VERSION ""

NS_ :

BS_:

BU_: CAN_open_MASTER MAXON RES AREO_PRESSURE_SENS DV_BOARD RPI_LOGGER AREO_TEMP_SENS ANGLE_SENSOR BUZZER BRAKE_LIGHT MAIN SW LV_BMS Power_Module HV_BMS Pedals_frame GPS2CAN ADU FS_Datalogger
VAL_TABLE_ Service_brake_state_enum 3 "Service_brake_state_available" 2 "Service_brake_state_engaged" 1 "Service_brake_state_disengaged" ;
VAL_TABLE_ AMI_state_enum 6 "AMI_state_autocross" 5 "AMI_state_inspection" 4 "AMI_state_braketest" 3 "AMI_state_trackdrive" 2 "AMI_state_skidpad" 1 "AMI_state_acceleration" ;
VAL_TABLE_ EBS_state_enum 3 "EBS_state_activated" 2 "EBS_state_armed" 1 "EBS_state_unavailable" ;
VAL_TABLE_ AS_state_enum 5 "AS_state_finish" 4 "AS_state_emergency_brake" 3 "AS_state_driving " 2 "AS_state_ready" 1 "AS_state_off" ;

BO_ 6 ACCU_FAN_SPEED_REQUEST: 2 SW
 SG_ AccuFunSpeedSet : 8|8@1+ (1,0) [0|100] "%"  BRAKE_LIGHT
 SG_ AccuFunSpeedIncrease : 0|8@1- (1,0) [-100|100] "%"  BRAKE_LIGHT

BO_ 28 ACCU_FAN_SPEED: 1 BRAKE_LIGHT
 SG_ AccuFunSpeed : 0|8@1+ (1,0) [0|100] "%"  ADU

BO_ 31 MAIN_Driver_Flags: 8 MAIN
 SG_ amkModuleFlags : 8|8@1+ (1,0) [0|255] ""  SW,ADU
 SG_ currentDriver : 0|8@1+ (1,0) [0|255] ""  SW,ADU

BO_ 39 MAIN_PBalance_Osteer: 8 MAIN
 SG_ oversteer : 32|32@1+ (1,0) [0|4294967295] ""  SW,ADU
 SG_ powerBalance : 0|32@1+ (1,0) [0|4294967295] ""  SW,ADU

BO_ 38 MAIN_O_P_Q: 8 MAIN
 SG_ Q : 48|16@1+ (1,0) [0|65535] ""  SW,ADU
 SG_ P : 32|16@1+ (1,0) [0|65535] ""  SW,ADU
 SG_ O : 0|32@1+ (1,0) [0|4294967295] ""  SW,ADU

BO_ 37 MAIN_KL: 8 MAIN
 SG_ L : 32|32@1+ (1,0) [0|4294967295] ""  SW,ADU
 SG_ K : 0|32@1+ (1,0) [0|4294967295] ""  SW,ADU

BO_ 36 MAIN_YawSet_TVSpeed: 8 MAIN
 SG_ TVStartSpeed : 32|32@1+ (1,0) [0|4294967295] ""  SW,ADU
 SG_ yawSetpoint : 0|32@1+ (1,0) [0|4294967295] ""  SW,ADU

BO_ 35 MAIN_CFilter_PLimit: 8 MAIN
 SG_ powerLimit : 32|32@1+ (1,0) [0|4294967295] ""  SW,ADU
 SG_ complFilter : 0|32@1+ (1,0) [0|4294967295] ""  SW,ADU

BO_ 34 MAIN_Kd: 8 MAIN
 SG_ TCkd : 32|32@1+ (1,0) [0|4294967295] ""  SW,ADU
 SG_ TVKd : 0|32@1+ (1,0) [0|4294967295] ""  SW,ADU

BO_ 33 MAIN_Ki: 8 MAIN
 SG_ TCKi : 32|32@1+ (1,0) [0|4294967295] ""  SW,ADU
 SG_ TVKi : 0|32@1+ (1,0) [0|4294967295] ""  SW,ADU

BO_ 32 MAIN_Kp: 8 MAIN
 SG_ TCKp : 32|32@1+ (1,0) [0|4294967295] ""  SW,ADU
 SG_ TVKp : 0|32@1+ (1,0) [0|4294967295] ""  SW,ADU

BO_ 1034 LV_BMS_REQUEST_Frame: 1 SW
 SG_ LV_BMS_REQUEST_PowerCycle : 0|8@1+ (1,0) [0|255] ""  SW

BO_ 1328 JAGGORACY_PROC: 8 HV_BMS
 SG_ JAGGORACY_PROC : 0|8@1- (1,0) [-128|127] ""  ADU

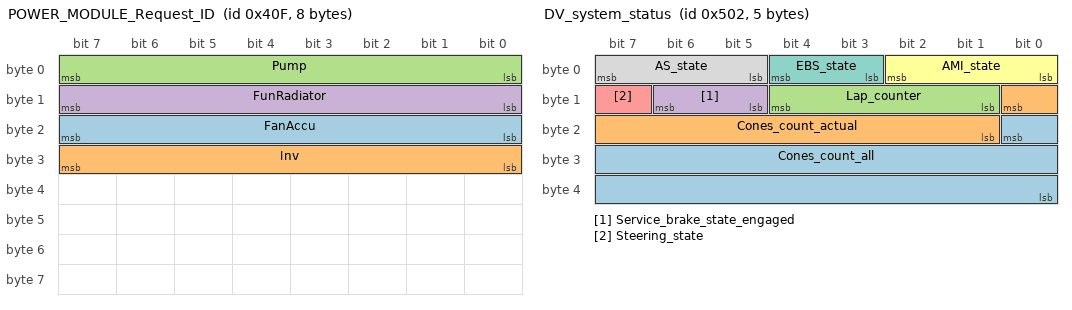
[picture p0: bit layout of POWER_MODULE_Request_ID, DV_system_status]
BO_ 1039 POWER_MODULE_Request_ID: 8 SW
 SG_ FanAccu : 23|8@0+ (1,0) [0|255] ""  Power_Module
 SG_ Inv : 31|8@0+ (1,0) [0|255] ""  Power_Module
 SG_ Pump : 7|8@0+ (1,0) [0|255] ""  Power_Module
 SG_ FunRadiator : 15|8@0+ (1,0) [0|255] ""  Power_Module

BO_ 1031 GPS_FRAME_7: 8 GPS2CAN

BO_ 1030 GPS_FRAME_6: 8 GPS2CAN

BO_ 1029 GPS_FRAME_5: 8 GPS2CAN

BO_ 1794 MAXON_NMT_Monitoring: 8 MAXON

BO_ 1154 MAXON_PDO_Transmit_4: 8 MAXON

BO_ 1791 Node_claiming_procedure_END: 8 CAN_open_MASTER

BO_ 1776 Node_claiming_procedure_BEGIN: 8 CAN_open_MASTER

BO_ 1763 Node_claiming_procedure_3: 8 CAN_open_MASTER

BO_ 1762 Node_claiming_procedure_2: 8 CAN_open_MASTER

BO_ 1761 Node_claiming_procedure_1: 8 CAN_open_MASTER

BO_ 1760 Dynamic_SDO_request: 8 CAN_open_MASTER

BO_ 384 Safety_Relevant_data_END: 8 CAN_open_MASTER

BO_ 257 Safety_Relevant_data_BEGIN: 8 CAN_open_MASTER

BO_ 118 Flying_master_END: 8 CAN_open_MASTER

BO_ 113 Flying_master_BEGIN: 8 CAN_open_MASTER

BO_ 3 MAXON_NMT_node_monitoring: 8 MAXON

BO_ 1538 MAXON_SDO_Receive: 8 MAXON

BO_ 1410 MAXON_SDO_Transmit: 8 MAXON

BO_ 2 MAXON_PDO_Receive_2: 8 MAXON

BO_ 898 MAXON_PDO_Transmit_2: 8 MAXON

BO_ 770 MAXON_PDO_Receive_1: 8 MAXON

BO_ 642 MAXON_PDO_Transmit_1: 8 MAXON

BO_ 514 MAXON_PDO_Receive: 8 MAXON

BO_ 386 MAXON_PDO_Transmit: 8 MAXON

BO_ 130 MAXON_Emergency_Transmit: 8 MAXON

BO_ 127 Indicate_active_interface: 8 CAN_open_MASTER

BO_ 1 Global_failsafe_command: 8 CAN_open_MASTER

BO_ 529 PDO_Receive: 8 RES

BO_ 401 PDO_Transmit: 8 RES

BO_ 1553 RES_SDO_Receive: 8 RES

BO_ 1425 RES_SDO_Transmit: 8 RES

BO_ 2021 LSS_Receive: 8 CAN_open_MASTER

BO_ 2020 LSS_Transmit: 8 CAN_open_MASTER

BO_ 1809 NMT_node_monitoring: 8 RES

BO_ 256 TimeStamp: 8 CAN_open_MASTER

BO_ 145 RES_Emergency: 8 RES

BO_ 128 Sync: 8 CAN_open_MASTER

BO_ 0 NMT_node_control: 8 CAN_open_MASTER

BO_ 1282 DV_system_status: 5 DV_BOARD
 SG_ Cones_count_all : 16|17@0+ (1,0) [0|4095] ""  FS_Datalogger
 SG_ Cones_count_actual : 8|8@0+ (1,0) [0|255] ""  FS_Datalogger
 SG_ Lap_counter : 12|4@0+ (1,0) [0|15] ""  FS_Datalogger
 SG_ Service_brake_state_engaged : 14|2@0+ (1,0) [0|1] ""  FS_Datalogger
 SG_ Steering_state : 15|1@0+ (1,0) [0|255] ""  FS_Datalogger
 SG_ AMI_state : 2|3@0+ (1,0) [0|7] ""  FS_Datalogger
 SG_ EBS_state : 4|2@0+ (1,0) [0|3] ""  FS_Datalogger
 SG_ AS_state : 7|3@0+ (1,0) [0|3] ""  FS_Datalogger

BO_ 1281 DV_driving_dynamics2: 6 DV_BOARD
 SG_ Acceleration_longitudinal : 7|16@0- (0.001953125,0) [-31.1296|31.1277] "m/s^2"  FS_Datalogger
 SG_ Acceleration_lateral : 23|16@0- (0.001953125,0) [-31.1296|31.1277] "m/s^2"  FS_Datalogger
 SG_ Yaw_rate : 39|16@0- (0.001953125,0) [-31.1296|31.1277] "deg/s^2"  FS_Datalogger

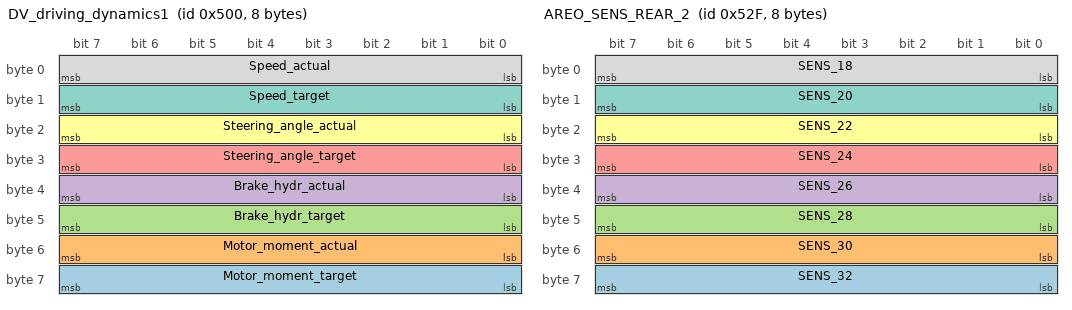
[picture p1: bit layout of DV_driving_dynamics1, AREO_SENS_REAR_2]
BO_ 1280 DV_driving_dynamics1: 8 DV_BOARD
 SG_ Motor_moment_target : 63|8@0- (1,0) [-128|127] "%"  FS_Datalogger
 SG_ Motor_moment_actual : 55|8@0- (1,0) [-128|127] "%"  FS_Datalogger
 SG_ Brake_hydr_target : 47|8@0+ (1,0) [0|255] "%"  FS_Datalogger
 SG_ Brake_hydr_actual : 39|8@0+ (1,0) [0|255] "%"  FS_Datalogger
 SG_ Steering_angle_target : 31|8@0- (0.5,0) [-128|127] ""  FS_Datalogger
 SG_ Steering_angle_actual : 23|8@0- (0.5,0) [-128|127] "deg"  FS_Datalogger
 SG_ Speed_target : 15|8@0+ (1,0) [0|255] "km/h"  FS_Datalogger
 SG_ Speed_actual : 7|8@0+ (1,0) [0|255] "km/h"  FS_Datalogger

BO_ 1327 AREO_SENS_REAR_2: 8 AREO_TEMP_SENS
 SG_ SENS_32 : 63|8@0+ (0.5,0) [0|127.5] "C"  RPI_LOGGER,ADU
 SG_ SENS_30 : 55|8@0+ (0.5,0) [0|127.5] "C"  RPI_LOGGER,ADU
 SG_ SENS_28 : 47|8@0+ (0.5,0) [0|127.5] "C"  RPI_LOGGER,ADU
 SG_ SENS_26 : 39|8@0+ (0.5,0) [0|127.5] "C"  RPI_LOGGER,ADU
 SG_ SENS_24 : 31|8@0+ (0.5,0) [0|127.5] "C"  RPI_LOGGER,ADU
 SG_ SENS_22 : 23|8@0+ (0.5,0) [0|127.5] "C"  RPI_LOGGER,ADU
 SG_ SENS_20 : 15|8@0+ (0.5,0) [0|127.5] "C"  RPI_LOGGER,ADU
 SG_ SENS_18 : 7|8@0+ (0.5,0) [0|127.5] "C"  RPI_LOGGER,ADU

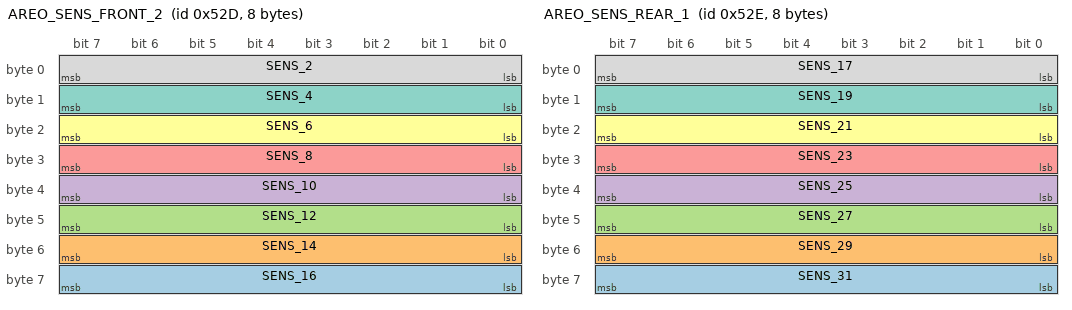
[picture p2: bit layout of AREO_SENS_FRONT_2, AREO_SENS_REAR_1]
BO_ 1325 AREO_SENS_FRONT_2: 8 AREO_TEMP_SENS
 SG_ SENS_16 : 63|8@0+ (0.5,0) [0|127.5] "C"  RPI_LOGGER,ADU
 SG_ SENS_14 : 55|8@0+ (0.5,0) [0|127.5] "C"  RPI_LOGGER,ADU
 SG_ SENS_12 : 47|8@0+ (0.5,0) [0|127.5] "C"  RPI_LOGGER,ADU
 SG_ SENS_10 : 39|8@0+ (0.5,0) [0|127.5] "C"  RPI_LOGGER,ADU
 SG_ SENS_8 : 31|8@0+ (0.5,0) [0|127.5] "C"  RPI_LOGGER,ADU
 SG_ SENS_6 : 23|8@0+ (0.5,0) [0|127.5] "C"  RPI_LOGGER,ADU
 SG_ SENS_4 : 15|8@0+ (0.5,0) [0|127.5] "C"  RPI_LOGGER,ADU
 SG_ SENS_2 : 7|8@0+ (0.5,0) [0|127.5] "C"  RPI_LOGGER,ADU

BO_ 1326 AREO_SENS_REAR_1: 8 AREO_TEMP_SENS
 SG_ SENS_31 : 63|8@0+ (0.5,0) [0|127.5] "C"  RPI_LOGGER,ADU
 SG_ SENS_29 : 55|8@0+ (0.5,0) [0|127.5] "C"  RPI_LOGGER,ADU
 SG_ SENS_27 : 47|8@0+ (0.5,0) [0|127.5] "C"  RPI_LOGGER,ADU
 SG_ SENS_25 : 39|8@0+ (0.5,0) [0|127.5] "C"  RPI_LOGGER,ADU
 SG_ SENS_23 : 31|8@0+ (0.5,0) [0|127.5] "C"  RPI_LOGGER,ADU
 SG_ SENS_21 : 23|8@0+ (0.5,0) [0|127.5] "C"  RPI_LOGGER,ADU
 SG_ SENS_19 : 15|8@0+ (0.5,0) [0|127.5] "C"  RPI_LOGGER,ADU
 SG_ SENS_17 : 7|8@0+ (0.5,0) [0|127.5] "C"  RPI_LOGGER,ADU

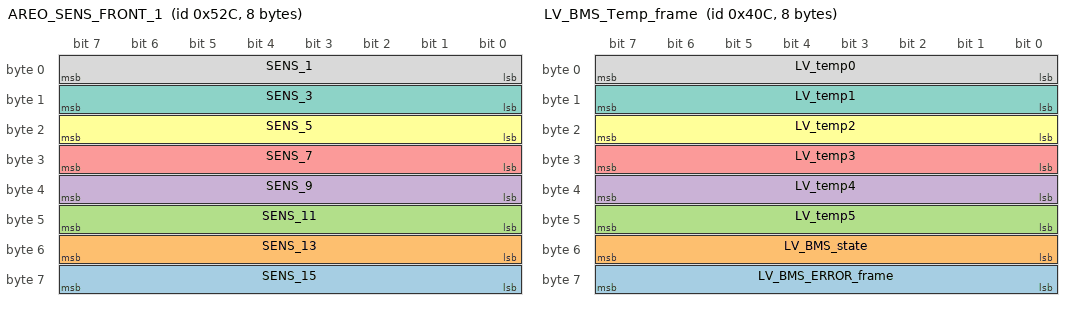
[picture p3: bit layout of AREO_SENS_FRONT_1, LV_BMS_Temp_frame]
BO_ 1324 AREO_SENS_FRONT_1: 8 AREO_TEMP_SENS
 SG_ SENS_15 : 63|8@0+ (0.5,0) [0|127.5] "C"  RPI_LOGGER,ADU
 SG_ SENS_13 : 55|8@0+ (0.5,0) [0|127.5] "C"  RPI_LOGGER,ADU
 SG_ SENS_11 : 47|8@0+ (0.5,0) [0|127.5] "C"  RPI_LOGGER,ADU
 SG_ SENS_9 : 39|8@0+ (0.5,0) [0|127.5] "C"  RPI_LOGGER,ADU
 SG_ SENS_7 : 31|8@0+ (0.5,0) [0|127.5] "C"  RPI_LOGGER,ADU
 SG_ SENS_5 : 23|8@0+ (0.5,0) [0|127.5] "C"  RPI_LOGGER,ADU
 SG_ SENS_3 : 15|8@0+ (0.5,0) [0|127.5] "C"  RPI_LOGGER,ADU
 SG_ SENS_1 : 7|8@0+ (0.5,0) [0|127.5] "C"  RPI_LOGGER,ADU

BO_ 1323 ANGLE_SENSOR_RL: 8 ANGLE_SENSOR
 SG_ WAS_ANGLE_RL_Error : 47|8@0+ (1,0) [0|255] ""  MAIN,ADU
 SG_ ANGLE_RL_Error : 39|8@0+ (1,0) [0|255] ""  MAIN,ADU
 SG_ ANGLE_RL : 7|32@0- (1E-006,0) [-2147.483648|2147.483647] "deg"  MAIN,ADU

BO_ 1322 ANGLE_SENSOR_RR: 8 ANGLE_SENSOR
 SG_ WAS_ANGLE_RR_Error : 47|8@0+ (1,0) [0|255] ""  MAIN,ADU
 SG_ ANGLE_RR_Error : 39|8@0+ (1,0) [0|255] ""  MAIN,ADU
 SG_ ANGLE_RR : 7|32@0- (1E-006,0) [-2147.483648|2147.483647] "deg"  MAIN,ADU

BO_ 1321 ANGLE_SENSOR_FL: 8 ANGLE_SENSOR
 SG_ WAS_ANGLE_FL_Error : 47|8@0+ (1,0) [0|255] ""  MAIN,ADU
 SG_ ANGLE_FL_Error : 39|8@0+ (1,0) [0|255] ""  MAIN,ADU
 SG_ ANGLE_FL : 7|32@0- (1E-006,0) [-2147.483648|2147.483647] "deg"  MAIN,ADU

BO_ 1320 ANGLE_SENSOR_FR: 8 ANGLE_SENSOR
 SG_ WAS_ANGLE_FR_Error : 47|8@0+ (1,0) [0|255] ""  MAIN,ADU
 SG_ ANGLE_FR_Error : 39|8@0+ (1,0) [0|255] ""  MAIN,ADU
 SG_ ANGLE_FR : 7|32@0- (1E-006,0) [-2147.483648|2147.483647] "deg"  MAIN,ADU

BO_ 1319 SW_SENSOR: 8 ANGLE_SENSOR
 SG_ WAS_ANGLE_SW_Error : 47|8@0+ (1,0) [0|255] ""  MAIN,ADU
 SG_ ANGLE_Error : 39|8@0+ (1,0) [0|255] ""  MAIN,ADU
 SG_ Angle : 7|32@0- (1E-006,0) [-2147.483648|2147.483647] "deg"  MAIN,ADU

BO_ 1318 BRAKE_LIGHT_frame: 1 ADU
 SG_ BRAKE_LIGHT_enable : 0|8@1- (1,0) [0|0] ""  BRAKE_LIGHT

BO_ 1317 BUZZER_frame: 1 ADU
 SG_ BUZZER_enable : 0|8@1+ (1,0) [0|255] ""  BUZZER

BO_ 1316 IVT_V3: 8 HV_BMS
 SG_ IVT_V3_Value : 16|32@1- (1,0) [-2147483648|2147483647] ""  ADU

BO_ 1315 IVT_V2: 8 HV_BMS
 SG_ IVT_V2_Value : 16|32@1- (0.001,0) [-2147483648|2147483647] "V"  ADU

BO_ 1314 IVT_V1: 8 HV_BMS
 SG_ IVT_V1_Value : 16|32@1- (0.001,0) [-2147483648|2147483647] "V"  ADU

BO_ 1313 IVT_I: 8 HV_BMS
 SG_ IVT_I_Value : 16|32@1- (0.1,0) [-2147483648|2147483647] "A?"  ADU

BO_ 1824 SW_MAIN_req_frame: 8 SW
 SG_ DriverNumber : 23|8@0+ (1,0) [0|255] ""  MAIN
 SG_ Limit : 15|8@0+ (1,0) [0|255] ""  MAIN
 SG_ Balance : 7|8@0- (1,0) [-128|127] ""  MAIN

BO_ 1036 LV_BMS_Temp_frame: 8 LV_BMS
 SG_ LV_BMS_ERROR_frame : 63|8@0+ (1,0) [0|255] ""  ADU
 SG_ LV_BMS_state : 55|8@0+ (1,0) [0|255] ""  ADU
 SG_ LV_temp5 : 47|8@0+ (1,0) [0|255] "C"  ADU
 SG_ LV_temp4 : 39|8@0+ (1,0) [0|255] "C"  ADU
 SG_ LV_temp3 : 31|8@0+ (1,0) [0|255] "C"  ADU
 SG_ LV_temp2 : 23|8@0+ (1,0) [0|255] "C"  ADU
 SG_ LV_temp1 : 15|8@0+ (1,0) [0|255] "C"  ADU
 SG_ LV_temp0 : 7|8@0+ (1,0) [0|255] "C"  ADU

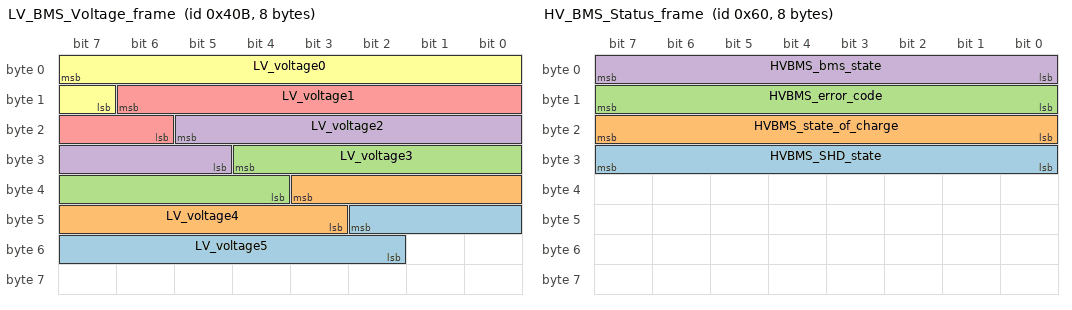
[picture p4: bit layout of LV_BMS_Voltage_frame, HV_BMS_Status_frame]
BO_ 1035 LV_BMS_Voltage_frame: 8 LV_BMS
 SG_ LV_voltage5 : 42|9@0+ (10,0) [0|5110] "mV"  ADU
 SG_ LV_voltage4 : 35|9@0+ (10,0) [0|5110] "mV"  ADU
 SG_ LV_voltage3 : 28|9@0+ (10,0) [0|5110] "mV"  ADU
 SG_ LV_voltage2 : 21|9@0+ (10,0) [0|5110] "mV"  ADU
 SG_ LV_voltage1 : 14|9@0+ (10,0) [0|5110] "mV"  ADU
 SG_ LV_voltage0 : 7|9@0+ (10,0) [0|5110] "mV"  ADU

BO_ 1038 POWER_MODULE_ERROR_ID: 1 Power_Module
 SG_ PowerModule_Error : 7|8@0+ (1,0) [0|255] ""  ADU,MAIN

BO_ 1407 V_T_Request_frame: 8 ADU
 SG_ Print_V_T : 0|8@1+ (1,0) [0|255] ""  HV_BMS

BO_ 95 HV_PWR_Limits_frame: 4 HV_BMS
 SG_ Discharge_current_limit : 0|16@1+ (1,0) [0|65535] ""  ADU,MAIN
 SG_ Charge_current_limit : 16|16@1+ (1,0) [0|65535] ""  ADU,MAIN

BO_ 96 HV_BMS_Status_frame: 8 HV_BMS
 SG_ HVBMS_SHD_state : 31|8@0+ (1,0) [0|255] ""  ADU,MAIN
 SG_ HVBMS_state_of_charge : 23|8@0+ (1,0) [0|255] ""  ADU,MAIN
 SG_ HVBMS_error_code : 15|8@0+ (1,0) [0|255] ""  ADU,MAIN
 SG_ HVBMS_bms_state : 7|8@0+ (1,0) [0|255] ""  ADU,MAIN

BO_ 97 HV_BMS_ERROR: 8 HV_BMS
 SG_ AMS_Warrnig : 32|32@1+ (1,0) [0|65535] ""  MAIN,ADU
 SG_ AMS_ERROR : 0|32@1+ (1,0) [0|65535] ""  MAIN,ADU

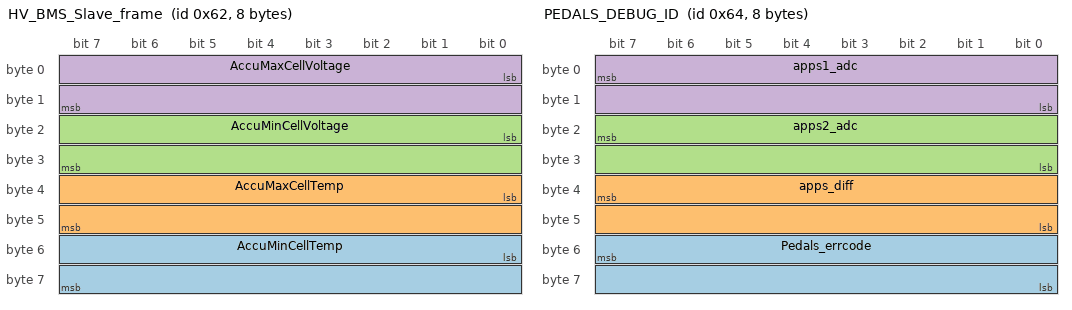
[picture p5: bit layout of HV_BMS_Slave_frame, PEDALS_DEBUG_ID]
BO_ 98 HV_BMS_Slave_frame: 8 HV_BMS
 SG_ AccuMinCellTemp : 48|16@1+ (0.1,0) [0|65535] "C"  BRAKE_LIGHT,ADU
 SG_ AccuMaxCellTemp : 32|16@1+ (0.1,0) [0|65535] "C"  BRAKE_LIGHT,ADU
 SG_ AccuMinCellVoltage : 16|16@1+ (1,0) [0|65535] "mV"  BRAKE_LIGHT,ADU
 SG_ AccuMaxCellVoltage : 0|16@1+ (1,0) [0|65535] "mV"  BRAKE_LIGHT,ADU

BO_ 101 HV_BMS_MAIN_Command_frame: 8 MAIN
 SG_ HV_BMS_command : 7|8@0+ (1,0) [0|255] ""  ADU,HV_BMS

BO_ 1793 SW_PEDALS_req_frame: 8 SW
 SG_ pedals_calib : 15|8@0+ (1,0) [0|255] ""  Pedals_frame
 SG_ bb_update : 7|8@0+ (1,0) [0|255] ""  Pedals_frame

BO_ 100 PEDALS_DEBUG_ID: 8 Pedals_frame
 SG_ Pedals_errcode : 55|16@0+ (1,0) [0|65535] ""  ADU
 SG_ apps_diff : 39|16@0- (1,0) [-32768|32767] ""  ADU
 SG_ apps2_adc : 23|16@0+ (1,0) [0|65535] ""  ADU
 SG_ apps1_adc : 7|16@0+ (1,0) [0|65535] ""  ADU

BO_ 1033 IMU_ACCELERATION_frame: 6 GPS2CAN
 SG_ HR_Z_accel : 39|16@0- (0.01,0) [-327.68|327.67] "g"  ADU,MAIN
 SG_ HR_Y_accel : 23|16@0- (0.01,0) [-327.68|327.67] "g"  ADU,MAIN
 SG_ HR_X_accel : 7|16@0- (0.01,0) [-327.68|327.67] "g"  ADU,MAIN

BO_ 1032 IMU_ANGULAR_frame: 6 GPS2CAN
 SG_ HR_Z_ang_rate : 39|16@0- (0.01,0) [-327.68|327.67] "deg/s"  ADU,MAIN
 SG_ HR_Y_ang_rate : 23|16@0- (0.01,0) [-327.68|327.67] "deg/s"  ADU,MAIN
 SG_ HR_X_ang_rate : 7|16@0- (0.01,0) [-327.68|327.67] "deg/s"  ADU,MAIN

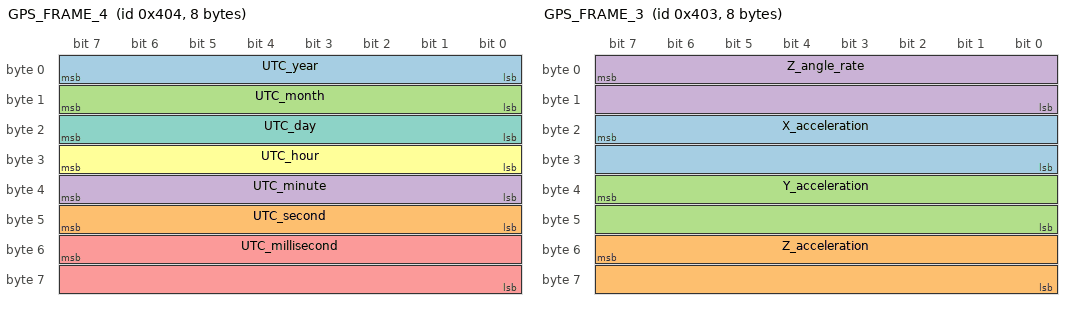
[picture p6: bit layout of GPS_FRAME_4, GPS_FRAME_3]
BO_ 1028 GPS_FRAME_4: 8 GPS2CAN
 SG_ UTC_year : 7|8@0+ (1,2000) [2000|2255] ""  ADU,MAIN
 SG_ UTC_second : 47|8@0+ (1,0) [0|255] ""  ADU,MAIN
 SG_ UTC_month : 15|8@0+ (1,0) [0|255] ""  ADU,MAIN
 SG_ UTC_minute : 39|8@0+ (1,0) [0|255] ""  ADU,MAIN
 SG_ UTC_millisecond : 55|16@0+ (0.01525878906,0) [0|999.9847410471] ""  ADU,MAIN
 SG_ UTC_hour : 31|8@0+ (1,0) [0|255] ""  ADU,MAIN
 SG_ UTC_day : 23|8@0+ (1,0) [0|255] ""  ADU,MAIN

BO_ 1027 GPS_FRAME_3: 8 GPS2CAN
 SG_ X_acceleration : 23|16@0- (0.01,0) [-327.68|327.67] "g"  ADU,MAIN
 SG_ Z_acceleration : 55|16@0- (0.01,0) [-327.68|327.67] "g"  ADU,MAIN
 SG_ Y_acceleration : 39|16@0- (0.01,0) [-327.68|327.67] "g"  ADU,MAIN
 SG_ Z_angle_rate : 7|16@0- (0.01,0) [-327.68|327.67] "deg/s"  ADU,MAIN

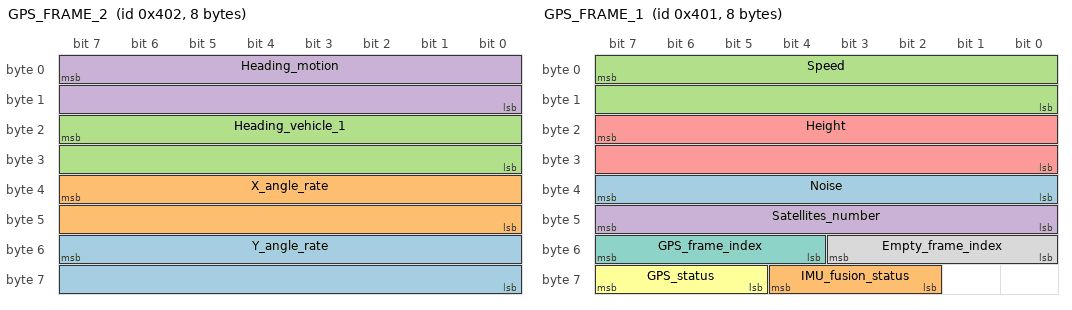
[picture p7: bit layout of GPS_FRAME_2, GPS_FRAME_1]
BO_ 1026 GPS_FRAME_2: 8 GPS2CAN
 SG_ Y_angle_rate : 55|16@0- (0.01,0) [-327.68|327.67] "deg/s"  ADU,MAIN
 SG_ X_angle_rate : 39|16@0- (0.01,0) [-327.68|327.67] "deg/s"  ADU,MAIN
 SG_ Heading_vehicle_1 : 23|16@0+ (1,0) [0|65535] ""  ADU,MAIN
 SG_ Heading_motion : 7|16@0+ (1,0) [0|65535] ""  ADU,MAIN

BO_ 1025 GPS_FRAME_1: 8 GPS2CAN
 SG_ Noise : 39|8@0+ (1,0) [0|255] ""  ADU
 SG_ IMU_fusion_status : 60|3@0+ (1,0) [0|7] ""  ADU
 SG_ Speed : 7|16@0- (0.036,0) [-1179.648|1179.612] "km/h"  ADU,MAIN
 SG_ Satellites_number : 47|8@0+ (1,0) [0|255] ""  ADU,MAIN
 SG_ Height : 23|16@0- (1,0) [-32768|32767] "m"  ADU,MAIN
 SG_ GPS_status : 63|3@0+ (1,0) [0|7] ""  ADU,MAIN
 SG_ GPS_frame_index : 55|4@0+ (1,0) [0|15] ""  ADU,MAIN
 SG_ Empty_frame_index : 51|4@0+ (1,0) [0|15] ""  ADU,MAIN

BO_ 1024 GPS_FRAME_0: 8 GPS2CAN
 SG_ Latitude : 7|32@0- (1E-007,0) [-214.7483648|214.7483647] ""  ADU,MAIN
 SG_ Longitude : 39|32@0- (1E-007,0) [-214.7483648|214.7483647] ""  ADU,MAIN

BO_ 17 StartButtons: 2 ADU
 SG_ Hv_on : 0|8@1+ (1,0) [0|255] ""  MAIN
 SG_ TS_on : 8|8@1+ (1,0) [0|255] ""  MAIN

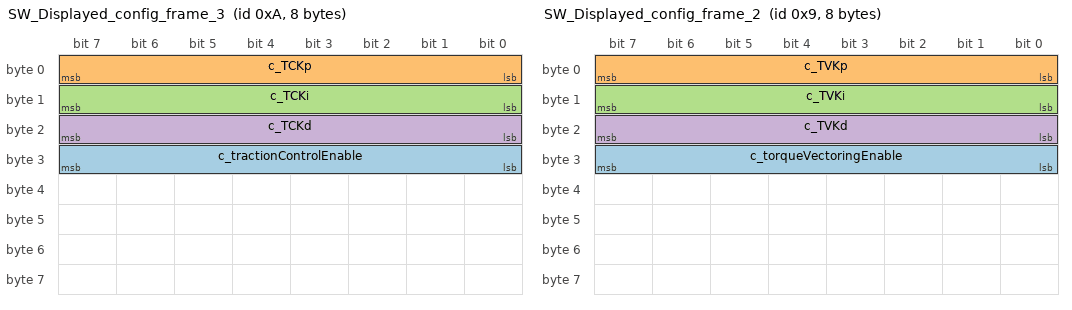
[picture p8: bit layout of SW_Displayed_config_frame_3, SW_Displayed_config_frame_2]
BO_ 10 SW_Displayed_config_frame_3: 8 SW
 SG_ c_tractionControlEnable : 31|8@0+ (1,0) [0|255] ""  ADU
 SG_ c_TCKp : 7|8@0+ (1,0) [0|255] ""  ADU
 SG_ c_TCKi : 15|8@0+ (1,0) [0|255] ""  ADU
 SG_ c_TCKd : 23|8@0+ (1,0) [0|255] ""  ADU

BO_ 9 SW_Displayed_config_frame_2: 8 SW
 SG_ c_torqueVectoringEnable : 31|8@0+ (1,0) [0|255] ""  ADU
 SG_ c_TVKp : 7|8@0+ (1,0) [0|255] ""  ADU
 SG_ c_TVKi : 15|8@0+ (1,0) [0|255] ""  ADU
 SG_ c_TVKd : 23|8@0+ (1,0) [0|255] ""  ADU

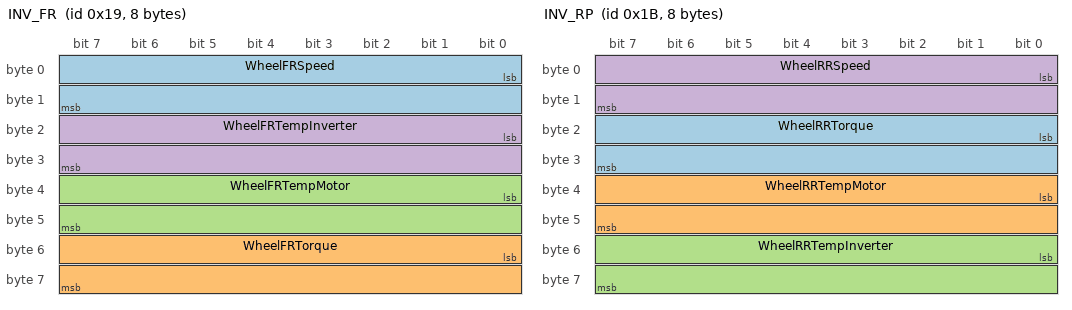
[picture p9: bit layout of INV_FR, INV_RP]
BO_ 25 INV_FR: 8 MAIN
 SG_ WheelFRSpeed : 0|16@1+ (1,0) [0|65535] ""  DV_BOARD,ADU
 SG_ WheelFRTorque : 48|16@1+ (1,0) [0|65535] ""  DV_BOARD,ADU
 SG_ WheelFRTempMotor : 32|16@1+ (1,0) [0|65535] ""  DV_BOARD,ADU
 SG_ WheelFRTempInverter : 16|16@1+ (1,0) [0|255] ""  DV_BOARD,ADU

BO_ 27 INV_RP: 8 MAIN
 SG_ WheelRRTorque : 16|16@1+ (1,0) [0|65535] ""  DV_BOARD,ADU
 SG_ WheelRRTempMotor : 32|16@1+ (1,0) [0|65535] ""  DV_BOARD,ADU
 SG_ WheelRRTempInverter : 48|16@1+ (1,0) [0|65535] ""  DV_BOARD,ADU
 SG_ WheelRRSpeed : 0|16@1+ (1,0) [0|65535] ""  DV_BOARD,ADU

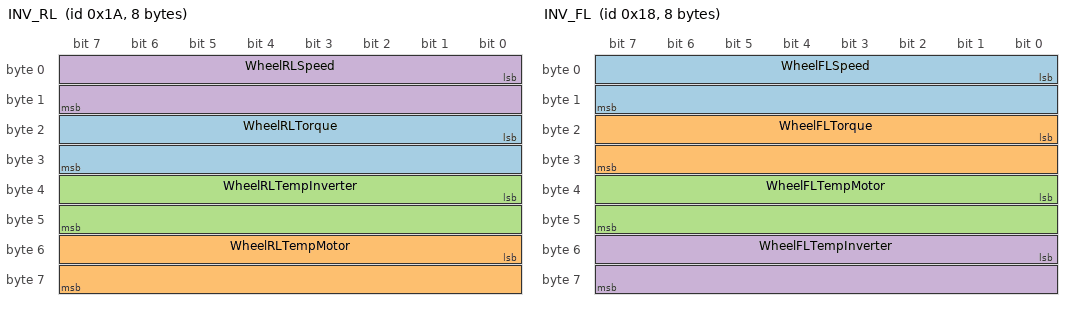
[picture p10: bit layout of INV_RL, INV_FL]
BO_ 26 INV_RL: 8 MAIN
 SG_ WheelRLTorque : 16|16@1+ (1,0) [0|65535] ""  DV_BOARD,ADU
 SG_ WheelRLTempMotor : 48|16@1+ (1,0) [0|65535] ""  DV_BOARD,ADU
 SG_ WheelRLTempInverter : 32|16@1+ (1,0) [0|65535] ""  DV_BOARD,ADU
 SG_ WheelRLSpeed : 0|16@1+ (1,0) [0|65535] ""  DV_BOARD,ADU

BO_ 24 INV_FL: 8 MAIN
 SG_ WheelFLSpeed : 0|16@1+ (1,0) [0|65535] ""  DV_BOARD,ADU
 SG_ WheelFLTorque : 16|16@1+ (1,0) [0|65535] ""  DV_BOARD,ADU
 SG_ WheelFLTempMotor : 32|16@1+ (1,0) [0|65535] ""  DV_BOARD,ADU
 SG_ WheelFLTempInverter : 48|16@1+ (1,0) [0|65535] ""  DV_BOARD,ADU

BO_ 7 SW: 8 SW
 SG_ Menulndex : 8|8@1+ (1,0) [0|255] ""  ADU
 SG_ ActiveTile : 0|8@1+ (1,0) [0|255] ""  ADU
 SG_ AduPage : 16|8@1+ (1,0) [0|255] ""  ADU

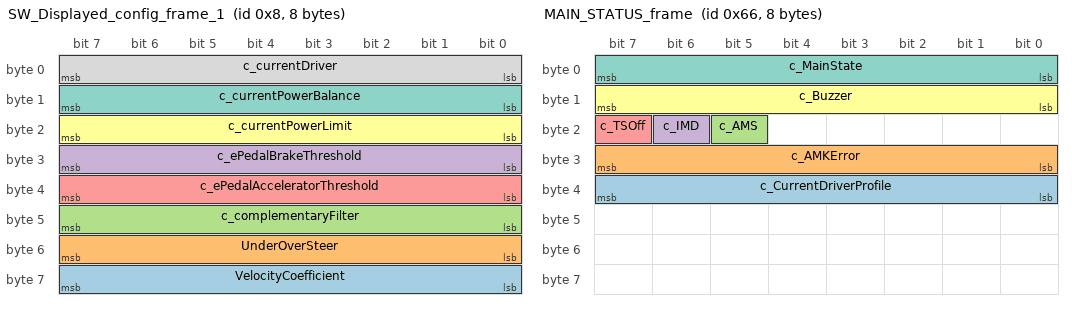
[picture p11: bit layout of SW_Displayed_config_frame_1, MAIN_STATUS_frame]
BO_ 8 SW_Displayed_config_frame_1: 8 SW
 SG_ VelocityCoefficient : 63|8@0+ (1,0) [0|255] ""  ADU
 SG_ UnderOverSteer : 55|8@0+ (1,0) [0|255] ""  ADU
 SG_ c_complementaryFilter : 47|8@0+ (1,0) [0|255] ""  ADU
 SG_ c_ePedalBrakeThreshold : 31|8@0+ (1,0) [0|255] ""  ADU
 SG_ c_ePedalAcceleratorThreshold : 39|8@0+ (1,0) [0|255] ""  ADU
 SG_ c_currentPowerLimit : 23|8@0+ (1,0) [0|255] ""  ADU
 SG_ c_currentPowerBalance : 15|8@0- (1,0) [-128|127] ""  ADU
 SG_ c_currentDriver : 7|8@0+ (1,0) [0|255] ""  ADU

BO_ 102 MAIN_STATUS_frame: 8 MAIN
 SG_ c_CurrentDriverProfile : 39|8@0+ (1,0) [0|255] ""  ADU
 SG_ c_AMKError : 31|8@0+ (1,0) [0|255] ""  ADU
 SG_ c_AMS : 21|1@0+ (1,0) [0|255] ""  ADU
 SG_ c_IMD : 22|1@0+ (1,0) [0|1] ""  ADU
 SG_ c_TSOff : 23|1@0+ (1,0) [0|1] ""  ADU
 SG_ c_Buzzer : 15|8@0+ (1,0) [0|255] ""  ADU
 SG_ c_MainState : 7|8@0+ (1,0) [0|255] ""  ADU

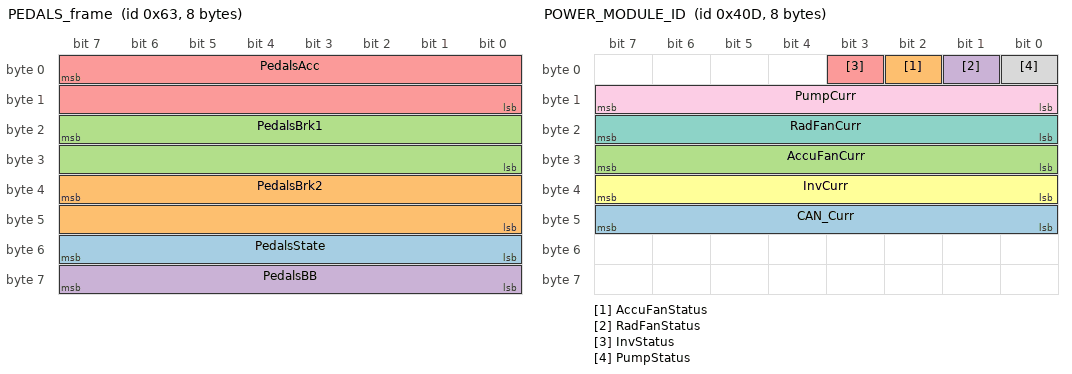
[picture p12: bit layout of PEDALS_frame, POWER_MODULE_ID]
BO_ 99 PEDALS_frame: 8 Pedals_frame
 SG_ PedalsState : 55|8@0+ (1,0) [0|255] ""  MAIN,ADU
 SG_ PedalsBrk2 : 39|16@0+ (1,0) [0|65535] ""  MAIN,ADU
 SG_ PedalsBrk1 : 23|16@0+ (1,0) [0|65535] ""  MAIN,ADU
 SG_ PedalsBB : 63|8@0+ (1,0) [0|255] ""  MAIN,ADU
 SG_ PedalsAcc : 7|16@0+ (1,0) [0|1000] ""  MAIN,ADU

BO_ 1037 POWER_MODULE_ID: 8 Power_Module
 SG_ CAN_Curr : 40|8@1+ (1,0) [0|255] ""  ADU,MAIN
 SG_ AccuFanStatus : 2|1@1+ (1,0) [0|255] ""  ADU,MAIN
 SG_ AccuFanCurr : 24|8@1+ (1,0) [0|255] ""  ADU,MAIN
 SG_ RadFanStatus : 1|1@1+ (1,0) [0|255] ""  ADU,MAIN
 SG_ InvStatus : 3|1@1+ (1,0) [0|255] ""  ADU,MAIN
 SG_ InvCurr : 32|8@1+ (1,0) [0|255] ""  ADU,MAIN
 SG_ RadFanCurr : 16|8@1+ (1,0) [0|255] ""  ADU,MAIN
 SG_ PumpStatus : 0|1@1+ (1,0) [0|255] ""  ADU,MAIN
 SG_ PumpCurr : 8|8@1+ (1,0) [0|255] ""  ADU,MAIN

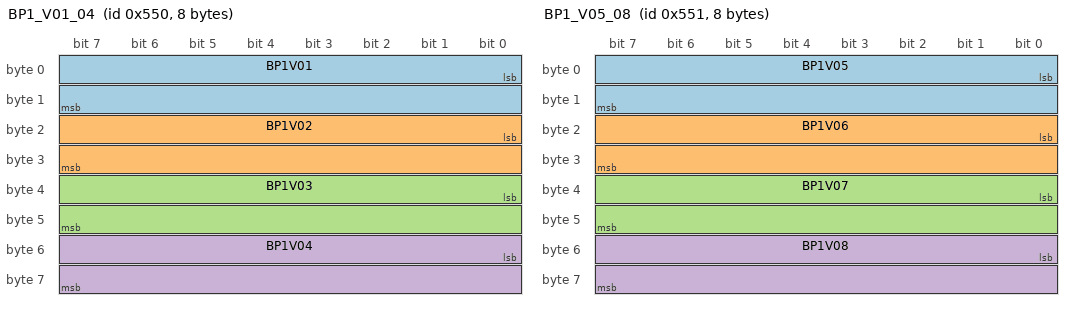
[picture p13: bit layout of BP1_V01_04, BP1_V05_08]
BO_ 1360 BP1_V01_04: 8 HV_BMS
 SG_ BP1V01 : 0|16@1+ (1,0) [0|65535] "mV"  RPI_LOGGER
 SG_ BP1V02 : 16|16@1+ (1,0) [0|65535] "mV"  RPI_LOGGER
 SG_ BP1V03 : 32|16@1+ (1,0) [0|65535] "mV"  RPI_LOGGER
 SG_ BP1V04 : 48|16@1+ (1,0) [0|65535] "mV"  RPI_LOGGER

BO_ 1361 BP1_V05_08: 8 HV_BMS
 SG_ BP1V05 : 0|16@1+ (1,0) [0|65535] "mV"  RPI_LOGGER
 SG_ BP1V06 : 16|16@1+ (1,0) [0|65535] "mV"  RPI_LOGGER
 SG_ BP1V07 : 32|16@1+ (1,0) [0|65535] "mV"  RPI_LOGGER
 SG_ BP1V08 : 48|16@1+ (1,0) [0|65535] "mV"  RPI_LOGGER

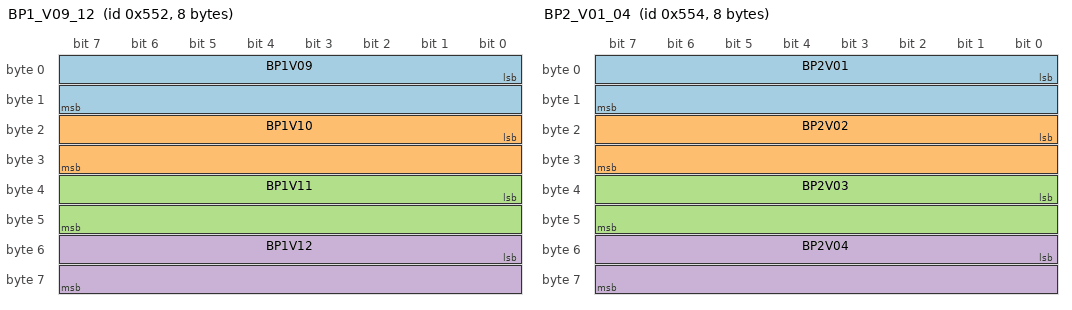
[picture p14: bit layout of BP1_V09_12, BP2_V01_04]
BO_ 1362 BP1_V09_12: 8 HV_BMS
 SG_ BP1V09 : 0|16@1+ (1,0) [0|65535] "mV"  RPI_LOGGER
 SG_ BP1V10 : 16|16@1+ (1,0) [0|65535] "mV"  RPI_LOGGER
 SG_ BP1V11 : 32|16@1+ (1,0) [0|65535] "mV"  RPI_LOGGER
 SG_ BP1V12 : 48|16@1+ (1,0) [0|65535] "mV"  RPI_LOGGER

BO_ 1363 BP1_V13_14: 8 HV_BMS
 SG_ BP1V13 : 0|16@1+ (1,0) [0|65535] "mV"  RPI_LOGGER
 SG_ BP1V14 : 16|16@1+ (1,0) [0|65535] "mV"  RPI_LOGGER

BO_ 1364 BP2_V01_04: 8 HV_BMS
 SG_ BP2V01 : 0|16@1+ (1,0) [0|65535] "mV"  RPI_LOGGER
 SG_ BP2V02 : 16|16@1+ (1,0) [0|65535] "mV"  RPI_LOGGER
 SG_ BP2V03 : 32|16@1+ (1,0) [0|65535] "mV"  RPI_LOGGER
 SG_ BP2V04 : 48|16@1+ (1,0) [0|65535] "mV"  RPI_LOGGER

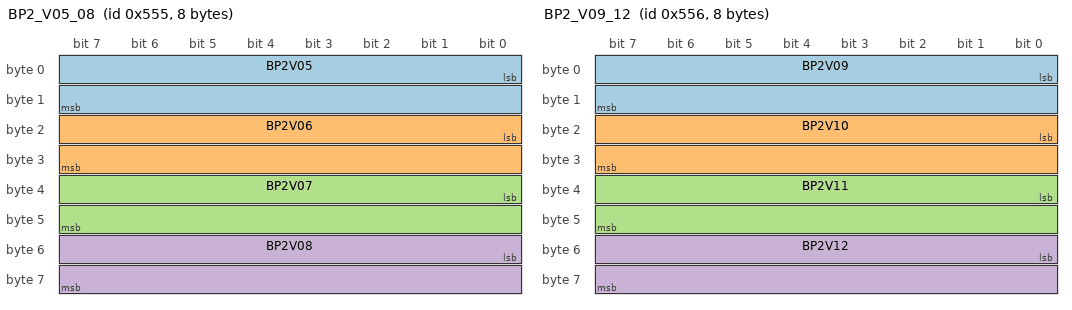
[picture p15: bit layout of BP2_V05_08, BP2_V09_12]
BO_ 1365 BP2_V05_08: 8 HV_BMS
 SG_ BP2V05 : 0|16@1+ (1,0) [0|65535] "mV"  RPI_LOGGER
 SG_ BP2V06 : 16|16@1+ (1,0) [0|65535] "mV"  RPI_LOGGER
 SG_ BP2V07 : 32|16@1+ (1,0) [0|65535] "mV"  RPI_LOGGER
 SG_ BP2V08 : 48|16@1+ (1,0) [0|65535] "mV"  RPI_LOGGER

BO_ 1366 BP2_V09_12: 8 HV_BMS
 SG_ BP2V09 : 0|16@1+ (1,0) [0|65535] "mV"  RPI_LOGGER
 SG_ BP2V10 : 16|16@1+ (1,0) [0|65535] "mV"  RPI_LOGGER
 SG_ BP2V11 : 32|16@1+ (1,0) [0|65535] "mV"  RPI_LOGGER
 SG_ BP2V12 : 48|16@1+ (1,0) [0|65535] "mV"  RPI_LOGGER

BO_ 1367 BP2_V13_14: 8 HV_BMS
 SG_ BP2V13 : 0|16@1+ (1,0) [0|65535] "mV"  RPI_LOGGER
 SG_ BP2V14 : 16|16@1+ (1,0) [0|65535] "mV"  RPI_LOGGER

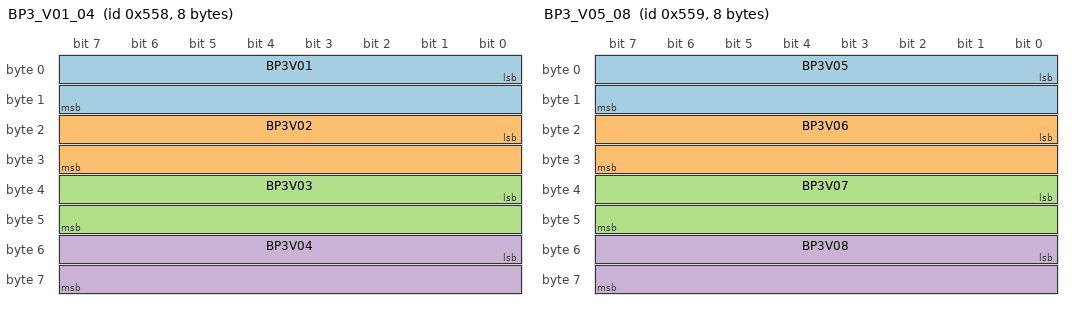
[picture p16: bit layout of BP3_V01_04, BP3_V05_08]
BO_ 1368 BP3_V01_04: 8 HV_BMS
 SG_ BP3V01 : 0|16@1+ (1,0) [0|65535] "mV"  RPI_LOGGER
 SG_ BP3V02 : 16|16@1+ (1,0) [0|65535] "mV"  RPI_LOGGER
 SG_ BP3V03 : 32|16@1+ (1,0) [0|65535] "mV"  RPI_LOGGER
 SG_ BP3V04 : 48|16@1+ (1,0) [0|65535] "mV"  RPI_LOGGER

BO_ 1369 BP3_V05_08: 8 HV_BMS
 SG_ BP3V05 : 0|16@1+ (1,0) [0|65535] "mV"  RPI_LOGGER
 SG_ BP3V06 : 16|16@1+ (1,0) [0|65535] "mV"  RPI_LOGGER
 SG_ BP3V07 : 32|16@1+ (1,0) [0|65535] "mV"  RPI_LOGGER
 SG_ BP3V08 : 48|16@1+ (1,0) [0|65535] "mV"  RPI_LOGGER

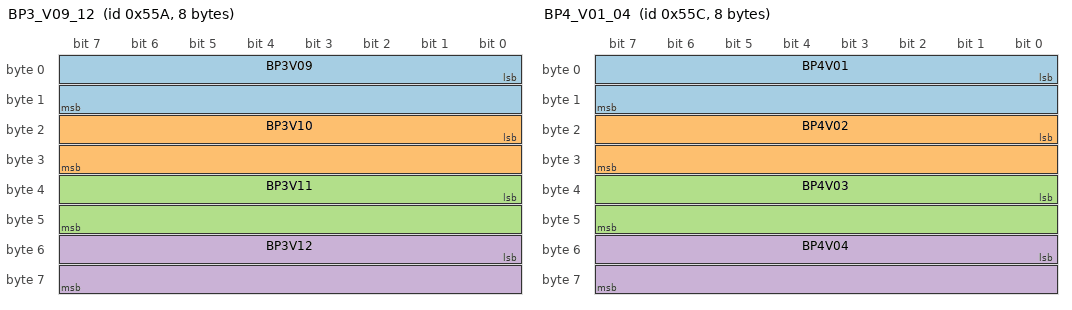
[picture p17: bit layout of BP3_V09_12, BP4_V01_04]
BO_ 1370 BP3_V09_12: 8 HV_BMS
 SG_ BP3V09 : 0|16@1+ (1,0) [0|65535] "mV"  RPI_LOGGER
 SG_ BP3V10 : 16|16@1+ (1,0) [0|65535] "mV"  RPI_LOGGER
 SG_ BP3V11 : 32|16@1+ (1,0) [0|65535] "mV"  RPI_LOGGER
 SG_ BP3V12 : 48|16@1+ (1,0) [0|65535] "mV"  RPI_LOGGER

BO_ 1371 BP3_V13_14: 8 HV_BMS
 SG_ BP3V13 : 0|16@1+ (1,0) [0|65535] "mV"  RPI_LOGGER
 SG_ BP3V14 : 16|16@1+ (1,0) [0|65535] "mV"  RPI_LOGGER

BO_ 1372 BP4_V01_04: 8 HV_BMS
 SG_ BP4V01 : 0|16@1+ (1,0) [0|65535] "mV"  RPI_LOGGER
 SG_ BP4V02 : 16|16@1+ (1,0) [0|65535] "mV"  RPI_LOGGER
 SG_ BP4V03 : 32|16@1+ (1,0) [0|65535] "mV"  RPI_LOGGER
 SG_ BP4V04 : 48|16@1+ (1,0) [0|65535] "mV"  RPI_LOGGER

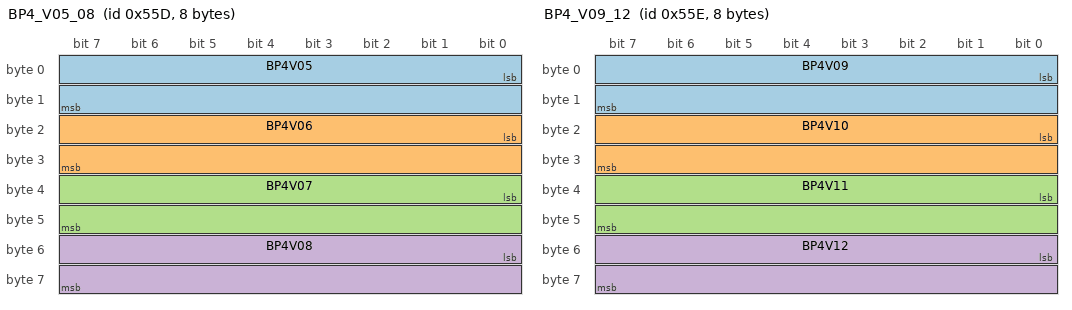
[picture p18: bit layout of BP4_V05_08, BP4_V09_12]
BO_ 1373 BP4_V05_08: 8 HV_BMS
 SG_ BP4V05 : 0|16@1+ (1,0) [0|65535] "mV"  RPI_LOGGER
 SG_ BP4V06 : 16|16@1+ (1,0) [0|65535] "mV"  RPI_LOGGER
 SG_ BP4V07 : 32|16@1+ (1,0) [0|65535] "mV"  RPI_LOGGER
 SG_ BP4V08 : 48|16@1+ (1,0) [0|65535] "mV"  RPI_LOGGER

BO_ 1374 BP4_V09_12: 8 HV_BMS
 SG_ BP4V09 : 0|16@1+ (1,0) [0|65535] "mV"  RPI_LOGGER
 SG_ BP4V10 : 16|16@1+ (1,0) [0|65535] "mV"  RPI_LOGGER
 SG_ BP4V11 : 32|16@1+ (1,0) [0|65535] "mV"  RPI_LOGGER
 SG_ BP4V12 : 48|16@1+ (1,0) [0|65535] "mV"  RPI_LOGGER

BO_ 1375 BP4_V13_14: 8 HV_BMS
 SG_ BP4V13 : 0|16@1+ (1,0) [0|65535] "mV"  RPI_LOGGER
 SG_ BP4V14 : 16|16@1+ (1,0) [0|65535] "mV"  RPI_LOGGER

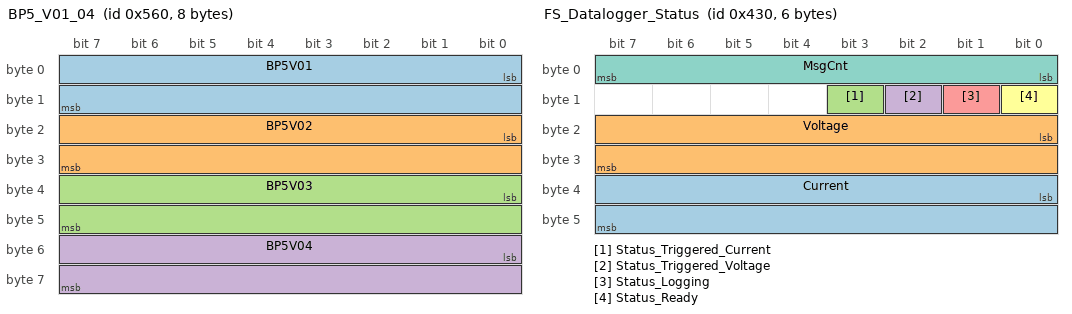
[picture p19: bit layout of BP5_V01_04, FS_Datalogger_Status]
BO_ 1376 BP5_V01_04: 8 HV_BMS
 SG_ BP5V01 : 0|16@1+ (1,0) [0|65535] "mV"  RPI_LOGGER
 SG_ BP5V02 : 16|16@1+ (1,0) [0|65535] "mV"  RPI_LOGGER
 SG_ BP5V03 : 32|16@1+ (1,0) [0|65535] "mV"  RPI_LOGGER
 SG_ BP5V04 : 48|16@1+ (1,0) [0|65535] "mV"  RPI_LOGGER

BO_ 1377 BP5_V05_08: 8 HV_BMS
 SG_ BP5V05 : 0|16@1+ (1,0) [0|65535] "mV"  RPI_LOGGER
 SG_ BP5V06 : 16|16@1+ (1,0) [0|65535] "mV"  RPI_LOGGER
 SG_ BP5V07 : 32|16@1+ (1,0) [0|65535] "mV"  RPI_LOGGER
 SG_ BP5V08 : 48|16@1+ (1,0) [0|65535] "mV"  RPI_LOGGER

BO_ 1378 BP5_V09_12: 8 HV_BMS
 SG_ BP5V09 : 0|16@1+ (1,0) [0|65535] "mV"  RPI_LOGGER
 SG_ BP5V10 : 16|16@1+ (1,0) [0|65535] "mV"  RPI_LOGGER
 SG_ BP5V11 : 32|16@1+ (1,0) [0|65535] "mV"  RPI_LOGGER
 SG_ BP5V12 : 48|16@1+ (1,0) [0|65535] "mV"  RPI_LOGGER

BO_ 1379 BP5_V13_14: 8 HV_BMS
 SG_ BP5V13 : 0|16@1+ (1,0) [0|65535] "mV"  RPI_LOGGER
 SG_ BP5V14 : 16|16@1+ (1,0) [0|65535] "mV"  RPI_LOGGER

BO_ 1380 BP6_V01_04: 8 HV_BMS
 SG_ BP6V01 : 0|16@1+ (1,0) [0|65535] "mV"  RPI_LOGGER
 SG_ BP6V02 : 16|16@1+ (1,0) [0|65535] "mV"  RPI_LOGGER
 SG_ BP6V03 : 32|16@1+ (1,0) [0|65535] "mV"  RPI_LOGGER
 SG_ BP6V04 : 48|16@1+ (1,0) [0|65535] "mV"  RPI_LOGGER

BO_ 1381 BP6_V05_08: 8 HV_BMS
 SG_ BP6V05 : 0|16@1+ (1,0) [0|65535] "mV"  RPI_LOGGER
 SG_ BP6V06 : 16|16@1+ (1,0) [0|65535] "mV"  RPI_LOGGER
 SG_ BP6V07 : 32|16@1+ (1,0) [0|65535] "mV"  RPI_LOGGER
 SG_ BP6V08 : 48|16@1+ (1,0) [0|65535] "mV"  RPI_LOGGER

BO_ 1382 BP6_V09_12: 8 HV_BMS
 SG_ BP6V09 : 0|16@1+ (1,0) [0|65535] "mV"  RPI_LOGGER
 SG_ BP6V10 : 16|16@1+ (1,0) [0|65535] "mV"  RPI_LOGGER
 SG_ BP6V11 : 32|16@1+ (1,0) [0|65535] "mV"  RPI_LOGGER
 SG_ BP6V12 : 48|16@1+ (1,0) [0|65535] "mV"  RPI_LOGGER

BO_ 1383 BP6_V13_14: 8 HV_BMS
 SG_ BP6V13 : 0|16@1+ (1,0) [0|65535] "mV"  RPI_LOGGER
 SG_ BP6V14 : 16|16@1+ (1,0) [0|65535] "mV"  RPI_LOGGER

BO_ 1384 BP7_V01_04: 8 HV_BMS
 SG_ BP7V01 : 0|16@1+ (1,0) [0|65535] "mV"  RPI_LOGGER
 SG_ BP7V02 : 16|16@1+ (1,0) [0|65535] "mV"  RPI_LOGGER
 SG_ BP7V03 : 32|16@1+ (1,0) [0|65535] "mV"  RPI_LOGGER
 SG_ BP7V04 : 48|16@1+ (1,0) [0|65535] "mV"  RPI_LOGGER

BO_ 1385 BP7_V05_08: 8 HV_BMS
 SG_ BP7V05 : 0|16@1+ (1,0) [0|65535] "mV"  RPI_LOGGER
 SG_ BP7V06 : 16|16@1+ (1,0) [0|65535] "mV"  RPI_LOGGER
 SG_ BP7V07 : 32|16@1+ (1,0) [0|65535] "mV"  RPI_LOGGER
 SG_ BP7V08 : 48|16@1+ (1,0) [0|65535] "mV"  RPI_LOGGER

BO_ 1386 BP7_V09_12: 8 HV_BMS
 SG_ BP7V09 : 0|16@1+ (1,0) [0|65535] "mV"  RPI_LOGGER
 SG_ BP7V10 : 16|16@1+ (1,0) [0|65535] "mV"  RPI_LOGGER
 SG_ BP7V11 : 32|16@1+ (1,0) [0|65535] "mV"  RPI_LOGGER
 SG_ BP7V12 : 48|16@1+ (1,0) [0|65535] "mV"  RPI_LOGGER

BO_ 1387 BP7_V13_14: 8 HV_BMS
 SG_ BP7V13 : 0|16@1+ (1,0) [0|65535] "mV"  RPI_LOGGER
 SG_ BP7V14 : 16|16@1+ (1,0) [0|65535] "mV"  RPI_LOGGER

BO_ 1388 BP8_V01_04: 8 HV_BMS
 SG_ BP8V01 : 0|16@1+ (1,0) [0|65535] "mV"  RPI_LOGGER
 SG_ BP8V02 : 16|16@1+ (1,0) [0|65535] "mV"  RPI_LOGGER
 SG_ BP8V03 : 32|16@1+ (1,0) [0|65535] "mV"  RPI_LOGGER
 SG_ BP8V04 : 48|16@1+ (1,0) [0|65535] "mV"  RPI_LOGGER

BO_ 1389 BP8_V05_08: 8 HV_BMS
 SG_ BP8V05 : 0|16@1+ (1,0) [0|65535] "mV"  RPI_LOGGER
 SG_ BP8V06 : 16|16@1+ (1,0) [0|65535] "mV"  RPI_LOGGER
 SG_ BP8V07 : 32|16@1+ (1,0) [0|65535] "mV"  RPI_LOGGER
 SG_ BP8V08 : 48|16@1+ (1,0) [0|65535] "mV"  RPI_LOGGER

BO_ 1390 BP8_V09_12: 8 HV_BMS
 SG_ BP8V09 : 0|16@1+ (1,0) [0|65535] "mV"  RPI_LOGGER
 SG_ BP8V10 : 16|16@1+ (1,0) [0|65535] "mV"  RPI_LOGGER
 SG_ BP8V11 : 32|16@1+ (1,0) [0|65535] "mV"  RPI_LOGGER
 SG_ BP8V12 : 48|16@1+ (1,0) [0|65535] "mV"  RPI_LOGGER

BO_ 1391 BP8_V13_14: 8 HV_BMS
 SG_ BP8V13 : 0|16@1+ (1,0) [0|65535] "mV"  RPI_LOGGER
 SG_ BP8V14 : 16|16@1+ (1,0) [0|65535] "mV"  RPI_LOGGER

BO_ 1392 BP9_V01_04: 8 HV_BMS
 SG_ BP9V01 : 0|16@1+ (1,0) [0|65535] "mV"  RPI_LOGGER
 SG_ BP9V02 : 16|16@1+ (1,0) [0|65535] "mV"  RPI_LOGGER
 SG_ BP9V03 : 32|16@1+ (1,0) [0|65535] "mV"  RPI_LOGGER
 SG_ BP9V04 : 48|16@1+ (1,0) [0|65535] "mV"  RPI_LOGGER

BO_ 1393 BP9_V05_08: 8 HV_BMS
 SG_ BP9V05 : 0|16@1+ (1,0) [0|65535] "mV"  RPI_LOGGER
 SG_ BP9V06 : 16|16@1+ (1,0) [0|65535] "mV"  RPI_LOGGER
 SG_ BP9V07 : 32|16@1+ (1,0) [0|65535] "mV"  RPI_LOGGER
 SG_ BP9V08 : 48|16@1+ (1,0) [0|65535] "mV"  RPI_LOGGER

BO_ 1394 BP9_V09_12: 8 HV_BMS
 SG_ BP9V09 : 0|16@1+ (1,0) [0|65535] "mV"  RPI_LOGGER
 SG_ BP9V10 : 16|16@1+ (1,0) [0|65535] "mV"  RPI_LOGGER
 SG_ BP9V11 : 32|16@1+ (1,0) [0|65535] "mV"  RPI_LOGGER
 SG_ BP9V12 : 48|16@1+ (1,0) [0|65535] "mV"  RPI_LOGGER

BO_ 1395 BP9_V13_14: 8 HV_BMS
 SG_ BP9V13 : 0|16@1+ (1,0) [0|65535] "mV"  RPI_LOGGER
 SG_ BP9V14 : 16|16@1+ (1,0) [0|65535] "mV"  RPI_LOGGER

BO_ 1396 BP10_V01_04: 8 HV_BMS
 SG_ BP10V01 : 0|16@1+ (1,0) [0|65535] "mV"  RPI_LOGGER
 SG_ BP10V02 : 16|16@1+ (1,0) [0|65535] "mV"  RPI_LOGGER
 SG_ BP10V03 : 32|16@1+ (1,0) [0|65535] "mV"  RPI_LOGGER
 SG_ BP10V04 : 48|16@1+ (1,0) [0|65535] "mV"  RPI_LOGGER

BO_ 1397 BP10_V05_08: 8 HV_BMS
 SG_ BP10V05 : 0|16@1+ (1,0) [0|65535] "mV"  RPI_LOGGER
 SG_ BP10V06 : 16|16@1+ (1,0) [0|65535] "mV"  RPI_LOGGER
 SG_ BP10V07 : 32|16@1+ (1,0) [0|65535] "mV"  RPI_LOGGER
 SG_ BP10V08 : 48|16@1+ (1,0) [0|65535] "mV"  RPI_LOGGER

BO_ 1398 BP10_V09_12: 8 HV_BMS
 SG_ BP10V09 : 0|16@1+ (1,0) [0|65535] "mV"  RPI_LOGGER
 SG_ BP10V10 : 16|16@1+ (1,0) [0|65535] "mV"  RPI_LOGGER
 SG_ BP10V11 : 32|16@1+ (1,0) [0|65535] "mV"  RPI_LOGGER
 SG_ BP10V12 : 48|16@1+ (1,0) [0|65535] "mV"  RPI_LOGGER

BO_ 1399 BP10_V13_14: 8 HV_BMS
 SG_ BP10V13 : 0|16@1+ (1,0) [0|65535] "mV"  RPI_LOGGER
 SG_ BP10V14 : 16|16@1+ (1,0) [0|65535] "mV"  RPI_LOGGER

BO_ 1877 FS_Datalogger_Reserved_6: 8 FS_Datalogger

BO_ 1876 FS_Datalogger_Reserved_5: 8 FS_Datalogger

BO_ 1875 FS_Datalogger_Reserved_4: 8 FS_Datalogger

BO_ 1874 FS_Datalogger_Reserved_3: 8 FS_Datalogger

BO_ 1873 FS_Datalogger_Reserved_2: 8 FS_Datalogger

BO_ 1872 FS_Datalogger_Reserved_1: 8 FS_Datalogger

BO_ 1072 FS_Datalogger_Status: 6 FS_Datalogger
 SG_ Current : 32|16@1+ (64,0) [0|4194240] "mA"  DV_BOARD
 SG_ Voltage : 16|16@1+ (16,0) [0|1048560] "mV"  DV_BOARD
 SG_ Status_Triggered_Current : 11|1@1- (1,0) [0|0] ""  DV_BOARD
 SG_ Status_Triggered_Voltage : 10|1@1- (1,0) [0|0] ""  DV_BOARD
 SG_ Status_Logging : 9|1@1- (1,0) [0|0] ""  DV_BOARD
 SG_ Status_Ready : 8|1@1- (1,0) [0|0] ""  DV_BOARD
 SG_ MsgCnt : 0|8@1+ (1,0) [0|255] ""  DV_BOARD

BO_ 1888 BP01_T01_04: 8 HV_BMS
 SG_ BP01T01 : 0|16@1+ (0.1,0) [0|6553.5] "C"  RPI_LOGGER
 SG_ BP01T02 : 16|16@1+ (0.1,0) [0|6553.5] "C"  RPI_LOGGER
 SG_ BP01T03 : 32|16@1+ (0.1,0) [0|6553.5] "C"  RPI_LOGGER
 SG_ BP01T04 : 48|16@1+ (0.1,0) [0|6553.5] "C"  RPI_LOGGER

BO_ 1889 BP01_T05_08: 8 HV_BMS
 SG_ BP01T05 : 0|16@1+ (0.1,0) [0|6553.5] "C"  RPI_LOGGER
 SG_ BP01T06 : 16|16@1+ (0.1,0) [0|6553.5] "C"  RPI_LOGGER
 SG_ BP01T07 : 32|16@1+ (0.1,0) [0|6553.5] "C"  RPI_LOGGER
 SG_ BP01T08 : 48|16@1+ (0.1,0) [0|6553.5] "C"  RPI_LOGGER

BO_ 1890 BP01_T09_12: 8 HV_BMS
 SG_ BP01T09 : 0|16@1+ (0.1,0) [0|6553.5] "C"  RPI_LOGGER
 SG_ BP01T10 : 16|16@1+ (0.1,0) [0|6553.5] "C"  RPI_LOGGER
 SG_ BP01T11 : 32|16@1+ (0.1,0) [0|6553.5] "C"  RPI_LOGGER
 SG_ BP01T12 : 48|16@1+ (0.1,0) [0|6553.5] "C"  RPI_LOGGER

BO_ 1891 BP01_T13_16: 8 HV_BMS
 SG_ BP01T13 : 0|16@1+ (0.1,0) [0|6553.5] "C"  RPI_LOGGER
 SG_ BP01T14 : 16|16@1+ (0.1,0) [0|6553.5] "C"  RPI_LOGGER
 SG_ BP01T15 : 32|16@1+ (0.1,0) [0|6553.5] "C"  RPI_LOGGER
 SG_ BP01T16 : 48|16@1+ (0.1,0) [0|6553.5] "C"  RPI_LOGGER

BO_ 1892 BP01_T17_20: 8 HV_BMS
 SG_ BP01T17 : 0|16@1+ (0.1,0) [0|6553.5] "C"  RPI_LOGGER
 SG_ BP01T18 : 16|16@1+ (0.1,0) [0|6553.5] "C"  RPI_LOGGER
 SG_ BP01T19 : 32|16@1+ (0.1,0) [0|6553.5] "C"  RPI_LOGGER
 SG_ BP01T20 : 48|16@1+ (0.1,0) [0|6553.5] "C"  RPI_LOGGER

BO_ 1893 BP01_T21_24: 8 HV_BMS
 SG_ BP01T21 : 0|16@1+ (0.1,0) [0|6553.5] "C"  RPI_LOGGER
 SG_ BP01T22 : 16|16@1+ (0.1,0) [0|6553.5] "C"  RPI_LOGGER
 SG_ BP01T23 : 32|16@1+ (0.1,0) [0|6553.5] "C"  RPI_LOGGER
 SG_ BP01T24 : 48|16@1+ (0.1,0) [0|6553.5] "C"  RPI_LOGGER

BO_ 1894 BP02_T01_04: 8 HV_BMS
 SG_ BP02T01 : 0|16@1+ (0.1,0) [0|6553.5] "C"  RPI_LOGGER
 SG_ BP02T02 : 16|16@1+ (0.1,0) [0|6553.5] "C"  RPI_LOGGER
 SG_ BP02T03 : 32|16@1+ (0.1,0) [0|6553.5] "C"  RPI_LOGGER
 SG_ BP02T04 : 48|16@1+ (0.1,0) [0|6553.5] "C"  RPI_LOGGER

BO_ 1895 BP02_T05_08: 8 HV_BMS
 SG_ BP02T05 : 0|16@1+ (0.1,0) [0|6553.5] "C"  RPI_LOGGER
 SG_ BP02T06 : 16|16@1+ (0.1,0) [0|6553.5] "C"  RPI_LOGGER
 SG_ BP02T07 : 32|16@1+ (0.1,0) [0|6553.5] "C"  RPI_LOGGER
 SG_ BP02T08 : 48|16@1+ (0.1,0) [0|6553.5] "C"  RPI_LOGGER

BO_ 1896 BP02_T09_12: 8 HV_BMS
 SG_ BP02T09 : 0|16@1+ (0.1,0) [0|6553.5] "C"  RPI_LOGGER
 SG_ BP02T10 : 16|16@1+ (0.1,0) [0|6553.5] "C"  RPI_LOGGER
 SG_ BP02T11 : 32|16@1+ (0.1,0) [0|6553.5] "C"  RPI_LOGGER
 SG_ BP02T12 : 48|16@1+ (0.1,0) [0|6553.5] "C"  RPI_LOGGER

BO_ 1897 BP02_T13_16: 8 HV_BMS
 SG_ BP02T13 : 0|16@1+ (0.1,0) [0|6553.5] "C"  RPI_LOGGER
 SG_ BP02T14 : 16|16@1+ (0.1,0) [0|6553.5] "C"  RPI_LOGGER
 SG_ BP02T15 : 32|16@1+ (0.1,0) [0|6553.5] "C"  RPI_LOGGER
 SG_ BP02T16 : 48|16@1+ (0.1,0) [0|6553.5] "C"  RPI_LOGGER

BO_ 1898 BP02_T17_20: 8 HV_BMS
 SG_ BP02T17 : 0|16@1+ (0.1,0) [0|6553.5] "C"  RPI_LOGGER
 SG_ BP02T18 : 16|16@1+ (0.1,0) [0|6553.5] "C"  RPI_LOGGER
 SG_ BP02T19 : 32|16@1+ (0.1,0) [0|6553.5] "C"  RPI_LOGGER
 SG_ BP02T20 : 48|16@1+ (0.1,0) [0|6553.5] "C"  RPI_LOGGER

BO_ 1899 BP02_T21_24: 8 HV_BMS
 SG_ BP02T21 : 0|16@1+ (0.1,0) [0|6553.5] "C"  RPI_LOGGER
 SG_ BP02T22 : 16|16@1+ (0.1,0) [0|6553.5] "C"  RPI_LOGGER
 SG_ BP02T23 : 32|16@1+ (0.1,0) [0|6553.5] "C"  RPI_LOGGER
 SG_ BP02T24 : 48|16@1+ (0.1,0) [0|6553.5] "C"  RPI_LOGGER

BO_ 1900 BP03_T01_04: 8 HV_BMS
 SG_ BP03T01 : 0|16@1+ (0.1,0) [0|6553.5] "C"  RPI_LOGGER
 SG_ BP03T02 : 16|16@1+ (0.1,0) [0|6553.5] "C"  RPI_LOGGER
 SG_ BP03T03 : 32|16@1+ (0.1,0) [0|6553.5] "C"  RPI_LOGGER
 SG_ BP03T04 : 48|16@1+ (0.1,0) [0|6553.5] "C"  RPI_LOGGER

BO_ 1901 BP03_T05_08: 8 HV_BMS
 SG_ BP03T05 : 0|16@1+ (0.1,0) [0|6553.5] "C"  RPI_LOGGER
 SG_ BP03T06 : 16|16@1+ (0.1,0) [0|6553.5] "C"  RPI_LOGGER
 SG_ BP03T07 : 32|16@1+ (0.1,0) [0|6553.5] "C"  RPI_LOGGER
 SG_ BP03T08 : 48|16@1+ (0.1,0) [0|6553.5] "C"  RPI_LOGGER

BO_ 1902 BP03_T09_12: 8 HV_BMS
 SG_ BP03T09 : 0|16@1+ (0.1,0) [0|6553.5] "C"  RPI_LOGGER
 SG_ BP03T10 : 16|16@1+ (0.1,0) [0|6553.5] "C"  RPI_LOGGER
 SG_ BP03T11 : 32|16@1+ (0.1,0) [0|6553.5] "C"  RPI_LOGGER
 SG_ BP03T12 : 48|16@1+ (0.1,0) [0|6553.5] "C"  RPI_LOGGER

BO_ 1903 BP03_T13_16: 8 HV_BMS
 SG_ BP03T13 : 0|16@1+ (0.1,0) [0|6553.5] "C"  RPI_LOGGER
 SG_ BP03T14 : 16|16@1+ (0.1,0) [0|6553.5] "C"  RPI_LOGGER
 SG_ BP03T15 : 32|16@1+ (0.1,0) [0|6553.5] "C"  RPI_LOGGER
 SG_ BP03T16 : 48|16@1+ (0.1,0) [0|6553.5] "C"  RPI_LOGGER

BO_ 1904 BP03_T17_20: 8 HV_BMS
 SG_ BP03T17 : 0|16@1+ (0.1,0) [0|6553.5] "C"  RPI_LOGGER
 SG_ BP03T18 : 16|16@1+ (0.1,0) [0|6553.5] "C"  RPI_LOGGER
 SG_ BP03T19 : 32|16@1+ (0.1,0) [0|6553.5] "C"  RPI_LOGGER
 SG_ BP03T20 : 48|16@1+ (0.1,0) [0|6553.5] "C"  RPI_LOGGER

BO_ 1905 BP03_T21_24: 8 HV_BMS
 SG_ BP03T21 : 0|16@1+ (0.1,0) [0|6553.5] "C"  RPI_LOGGER
 SG_ BP03T22 : 16|16@1+ (0.1,0) [0|6553.5] "C"  RPI_LOGGER
 SG_ BP03T23 : 32|16@1+ (0.1,0) [0|6553.5] "C"  RPI_LOGGER
 SG_ BP03T24 : 48|16@1+ (0.1,0) [0|6553.5] "C"  RPI_LOGGER

BO_ 1906 BP04_T01_04: 8 HV_BMS
 SG_ BP04T01 : 0|16@1+ (0.1,0) [0|6553.5] "C"  RPI_LOGGER
 SG_ BP04T02 : 16|16@1+ (0.1,0) [0|6553.5] "C"  RPI_LOGGER
 SG_ BP04T03 : 32|16@1+ (0.1,0) [0|6553.5] "C"  RPI_LOGGER
 SG_ BP04T04 : 48|16@1+ (0.1,0) [0|6553.5] "C"  RPI_LOGGER

BO_ 1907 BP04_T05_08: 8 HV_BMS
 SG_ BP04T05 : 0|16@1+ (0.1,0) [0|6553.5] "C"  RPI_LOGGER
 SG_ BP04T06 : 16|16@1+ (0.1,0) [0|6553.5] "C"  RPI_LOGGER
 SG_ BP04T07 : 32|16@1+ (0.1,0) [0|6553.5] "C"  RPI_LOGGER
 SG_ BP04T08 : 48|16@1+ (0.1,0) [0|6553.5] "C"  RPI_LOGGER

BO_ 1908 BP04_T09_12: 8 HV_BMS
 SG_ BP04T09 : 0|16@1+ (0.1,0) [0|6553.5] "C"  RPI_LOGGER
 SG_ BP04T10 : 16|16@1+ (0.1,0) [0|6553.5] "C"  RPI_LOGGER
 SG_ BP04T11 : 32|16@1+ (0.1,0) [0|6553.5] "C"  RPI_LOGGER
 SG_ BP04T12 : 48|16@1+ (0.1,0) [0|6553.5] "C"  RPI_LOGGER

BO_ 1909 BP04_T13_16: 8 HV_BMS
 SG_ BP04T13 : 0|16@1+ (0.1,0) [0|6553.5] "C"  RPI_LOGGER
 SG_ BP04T14 : 16|16@1+ (0.1,0) [0|6553.5] "C"  RPI_LOGGER
 SG_ BP04T15 : 32|16@1+ (0.1,0) [0|6553.5] "C"  RPI_LOGGER
 SG_ BP04T16 : 48|16@1+ (0.1,0) [0|6553.5] "C"  RPI_LOGGER

BO_ 1910 BP04_T17_20: 8 HV_BMS
 SG_ BP04T17 : 0|16@1+ (0.1,0) [0|6553.5] "C"  RPI_LOGGER
 SG_ BP04T18 : 16|16@1+ (0.1,0) [0|6553.5] "C"  RPI_LOGGER
 SG_ BP04T19 : 32|16@1+ (0.1,0) [0|6553.5] "C"  RPI_LOGGER
 SG_ BP04T20 : 48|16@1+ (0.1,0) [0|6553.5] "C"  RPI_LOGGER

BO_ 1911 BP04_T21_24: 8 HV_BMS
 SG_ BP04T21 : 0|16@1+ (0.1,0) [0|6553.5] "C"  RPI_LOGGER
 SG_ BP04T22 : 16|16@1+ (0.1,0) [0|6553.5] "C"  RPI_LOGGER
 SG_ BP04T23 : 32|16@1+ (0.1,0) [0|6553.5] "C"  RPI_LOGGER
 SG_ BP04T24 : 48|16@1+ (0.1,0) [0|6553.5] "C"  RPI_LOGGER

BO_ 1912 BP05_T01_04: 8 HV_BMS
 SG_ BP05T01 : 0|16@1+ (0.1,0) [0|6553.5] "C"  RPI_LOGGER
 SG_ BP05T02 : 16|16@1+ (0.1,0) [0|6553.5] "C"  RPI_LOGGER
 SG_ BP05T03 : 32|16@1+ (0.1,0) [0|6553.5] "C"  RPI_LOGGER
 SG_ BP05T04 : 48|16@1+ (0.1,0) [0|6553.5] "C"  RPI_LOGGER

BO_ 1913 BP05_T05_08: 8 HV_BMS
 SG_ BP05T05 : 0|16@1+ (0.1,0) [0|6553.5] "C"  RPI_LOGGER
 SG_ BP05T06 : 16|16@1+ (0.1,0) [0|6553.5] "C"  RPI_LOGGER
 SG_ BP05T07 : 32|16@1+ (0.1,0) [0|6553.5] "C"  RPI_LOGGER
 SG_ BP05T08 : 48|16@1+ (0.1,0) [0|6553.5] "C"  RPI_LOGGER

BO_ 1914 BP05_T09_12: 8 HV_BMS
 SG_ BP05T09 : 0|16@1+ (0.1,0) [0|6553.5] "C"  RPI_LOGGER
 SG_ BP05T10 : 16|16@1+ (0.1,0) [0|6553.5] "C"  RPI_LOGGER
 SG_ BP05T11 : 32|16@1+ (0.1,0) [0|6553.5] "C"  RPI_LOGGER
 SG_ BP05T12 : 48|16@1+ (0.1,0) [0|6553.5] "C"  RPI_LOGGER

BO_ 1915 BP05_T13_16: 8 HV_BMS
 SG_ BP05T13 : 0|16@1+ (0.1,0) [0|6553.5] "C"  RPI_LOGGER
 SG_ BP05T14 : 16|16@1+ (0.1,0) [0|6553.5] "C"  RPI_LOGGER
 SG_ BP05T15 : 32|16@1+ (0.1,0) [0|6553.5] "C"  RPI_LOGGER
 SG_ BP05T16 : 48|16@1+ (0.1,0) [0|6553.5] "C"  RPI_LOGGER

BO_ 1916 BP05_T17_20: 8 HV_BMS
 SG_ BP05T17 : 0|16@1+ (0.1,0) [0|6553.5] "C"  RPI_LOGGER
 SG_ BP05T18 : 16|16@1+ (0.1,0) [0|6553.5] "C"  RPI_LOGGER
 SG_ BP05T19 : 32|16@1+ (0.1,0) [0|6553.5] "C"  RPI_LOGGER
 SG_ BP05T20 : 48|16@1+ (0.1,0) [0|6553.5] "C"  RPI_LOGGER

BO_ 1917 BP05_T21_24: 8 HV_BMS
 SG_ BP05T21 : 0|16@1+ (0.1,0) [0|6553.5] "C"  RPI_LOGGER
 SG_ BP05T22 : 16|16@1+ (0.1,0) [0|6553.5] "C"  RPI_LOGGER
 SG_ BP05T23 : 32|16@1+ (0.1,0) [0|6553.5] "C"  RPI_LOGGER
 SG_ BP05T24 : 48|16@1+ (0.1,0) [0|6553.5] "C"  RPI_LOGGER

BO_ 1918 BP06_T01_04: 8 HV_BMS
 SG_ BP06T01 : 0|16@1+ (0.1,0) [0|6553.5] "C"  RPI_LOGGER
 SG_ BP06T02 : 16|16@1+ (0.1,0) [0|6553.5] "C"  RPI_LOGGER
 SG_ BP06T03 : 32|16@1+ (0.1,0) [0|6553.5] "C"  RPI_LOGGER
 SG_ BP06T04 : 48|16@1+ (0.1,0) [0|6553.5] "C"  RPI_LOGGER

BO_ 1919 BP06_T05_08: 8 HV_BMS
 SG_ BP06T05 : 0|16@1+ (0.1,0) [0|6553.5] "C"  RPI_LOGGER
 SG_ BP06T06 : 16|16@1+ (0.1,0) [0|6553.5] "C"  RPI_LOGGER
 SG_ BP06T07 : 32|16@1+ (0.1,0) [0|6553.5] "C"  RPI_LOGGER
 SG_ BP06T08 : 48|16@1+ (0.1,0) [0|6553.5] "C"  RPI_LOGGER

BO_ 1920 BP06_T09_12: 8 HV_BMS
 SG_ BP06T09 : 0|16@1+ (0.1,0) [0|6553.5] "C"  RPI_LOGGER
 SG_ BP06T10 : 16|16@1+ (0.1,0) [0|6553.5] "C"  RPI_LOGGER
 SG_ BP06T11 : 32|16@1+ (0.1,0) [0|6553.5] "C"  RPI_LOGGER
 SG_ BP06T12 : 48|16@1+ (0.1,0) [0|6553.5] "C"  RPI_LOGGER

BO_ 1921 BP06_T13_16: 8 HV_BMS
 SG_ BP06T13 : 0|16@1+ (0.1,0) [0|6553.5] "C"  RPI_LOGGER
 SG_ BP06T14 : 16|16@1+ (0.1,0) [0|6553.5] "C"  RPI_LOGGER
 SG_ BP06T15 : 32|16@1+ (0.1,0) [0|6553.5] "C"  RPI_LOGGER
 SG_ BP06T16 : 48|16@1+ (0.1,0) [0|6553.5] "C"  RPI_LOGGER

BO_ 1922 BP06_T17_20: 8 HV_BMS
 SG_ BP06T17 : 0|16@1+ (0.1,0) [0|6553.5] "C"  RPI_LOGGER
 SG_ BP06T18 : 16|16@1+ (0.1,0) [0|6553.5] "C"  RPI_LOGGER
 SG_ BP06T19 : 32|16@1+ (0.1,0) [0|6553.5] "C"  RPI_LOGGER
 SG_ BP06T20 : 48|16@1+ (0.1,0) [0|6553.5] "C"  RPI_LOGGER

BO_ 1923 BP06_T21_24: 8 HV_BMS
 SG_ BP06T21 : 0|16@1+ (0.1,0) [0|6553.5] "C"  RPI_LOGGER
 SG_ BP06T22 : 16|16@1+ (0.1,0) [0|6553.5] "C"  RPI_LOGGER
 SG_ BP06T23 : 32|16@1+ (0.1,0) [0|6553.5] "C"  RPI_LOGGER
 SG_ BP06T24 : 48|16@1+ (0.1,0) [0|6553.5] "C"  RPI_LOGGER

BO_ 1924 BP07_T01_04: 8 HV_BMS
 SG_ BP07T01 : 0|16@1+ (0.1,0) [0|6553.5] "C"  RPI_LOGGER
 SG_ BP07T02 : 16|16@1+ (0.1,0) [0|6553.5] "C"  RPI_LOGGER
 SG_ BP07T03 : 32|16@1+ (0.1,0) [0|6553.5] "C"  RPI_LOGGER
 SG_ BP07T04 : 48|16@1+ (0.1,0) [0|6553.5] "C"  RPI_LOGGER

BO_ 1925 BP07_T05_08: 8 HV_BMS
 SG_ BP07T05 : 0|16@1+ (0.1,0) [0|6553.5] "C"  RPI_LOGGER
 SG_ BP07T06 : 16|16@1+ (0.1,0) [0|6553.5] "C"  RPI_LOGGER
 SG_ BP07T07 : 32|16@1+ (0.1,0) [0|6553.5] "C"  RPI_LOGGER
 SG_ BP07T08 : 48|16@1+ (0.1,0) [0|6553.5] "C"  RPI_LOGGER

BO_ 1926 BP07_T09_12: 8 HV_BMS
 SG_ BP07T09 : 0|16@1+ (0.1,0) [0|6553.5] "C"  RPI_LOGGER
 SG_ BP07T10 : 16|16@1+ (0.1,0) [0|6553.5] "C"  RPI_LOGGER
 SG_ BP07T11 : 32|16@1+ (0.1,0) [0|6553.5] "C"  RPI_LOGGER
 SG_ BP07T12 : 48|16@1+ (0.1,0) [0|6553.5] "C"  RPI_LOGGER

BO_ 1927 BP07_T13_16: 8 HV_BMS
 SG_ BP07T13 : 0|16@1+ (0.1,0) [0|6553.5] "C"  RPI_LOGGER
 SG_ BP07T14 : 16|16@1+ (0.1,0) [0|6553.5] "C"  RPI_LOGGER
 SG_ BP07T15 : 32|16@1+ (0.1,0) [0|6553.5] "C"  RPI_LOGGER
 SG_ BP07T16 : 48|16@1+ (0.1,0) [0|6553.5] "C"  RPI_LOGGER

BO_ 1928 BP07_T17_20: 8 HV_BMS
 SG_ BP07T17 : 0|16@1+ (0.1,0) [0|6553.5] "C"  RPI_LOGGER
 SG_ BP07T18 : 16|16@1+ (0.1,0) [0|6553.5] "C"  RPI_LOGGER
 SG_ BP07T19 : 32|16@1+ (0.1,0) [0|6553.5] "C"  RPI_LOGGER
 SG_ BP07T20 : 48|16@1+ (0.1,0) [0|6553.5] "C"  RPI_LOGGER

BO_ 1929 BP07_T21_24: 8 HV_BMS
 SG_ BP07T21 : 0|16@1+ (0.1,0) [0|6553.5] "C"  RPI_LOGGER
 SG_ BP07T22 : 16|16@1+ (0.1,0) [0|6553.5] "C"  RPI_LOGGER
 SG_ BP07T23 : 32|16@1+ (0.1,0) [0|6553.5] "C"  RPI_LOGGER
 SG_ BP07T24 : 48|16@1+ (0.1,0) [0|6553.5] "C"  RPI_LOGGER

BO_ 1930 BP08_T01_04: 8 HV_BMS
 SG_ BP08T01 : 0|16@1+ (0.1,0) [0|6553.5] "C"  RPI_LOGGER
 SG_ BP08T02 : 16|16@1+ (0.1,0) [0|6553.5] "C"  RPI_LOGGER
 SG_ BP08T03 : 32|16@1+ (0.1,0) [0|6553.5] "C"  RPI_LOGGER
 SG_ BP08T04 : 48|16@1+ (0.1,0) [0|6553.5] "C"  RPI_LOGGER

BO_ 1931 BP08_T05_08: 8 HV_BMS
 SG_ BP08T05 : 0|16@1+ (0.1,0) [0|6553.5] "C"  RPI_LOGGER
 SG_ BP08T06 : 16|16@1+ (0.1,0) [0|6553.5] "C"  RPI_LOGGER
 SG_ BP08T07 : 32|16@1+ (0.1,0) [0|6553.5] "C"  RPI_LOGGER
 SG_ BP08T08 : 48|16@1+ (0.1,0) [0|6553.5] "C"  RPI_LOGGER

BO_ 1932 BP08_T09_12: 8 HV_BMS
 SG_ BP08T09 : 0|16@1+ (0.1,0) [0|6553.5] "C"  RPI_LOGGER
 SG_ BP08T10 : 16|16@1+ (0.1,0) [0|6553.5] "C"  RPI_LOGGER
 SG_ BP08T11 : 32|16@1+ (0.1,0) [0|6553.5] "C"  RPI_LOGGER
 SG_ BP08T12 : 48|16@1+ (0.1,0) [0|6553.5] "C"  RPI_LOGGER

BO_ 1933 BP08_T13_16: 8 HV_BMS
 SG_ BP08T13 : 0|16@1+ (0.1,0) [0|6553.5] "C"  RPI_LOGGER
 SG_ BP08T14 : 16|16@1+ (0.1,0) [0|6553.5] "C"  RPI_LOGGER
 SG_ BP08T15 : 32|16@1+ (0.1,0) [0|6553.5] "C"  RPI_LOGGER
 SG_ BP08T16 : 48|16@1+ (0.1,0) [0|6553.5] "C"  RPI_LOGGER

BO_ 1934 BP08_T17_20: 8 HV_BMS
 SG_ BP08T17 : 0|16@1+ (0.1,0) [0|6553.5] "C"  RPI_LOGGER
 SG_ BP08T18 : 16|16@1+ (0.1,0) [0|6553.5] "C"  RPI_LOGGER
 SG_ BP08T19 : 32|16@1+ (0.1,0) [0|6553.5] "C"  RPI_LOGGER
 SG_ BP08T20 : 48|16@1+ (0.1,0) [0|6553.5] "C"  RPI_LOGGER

BO_ 1935 BP08_T21_24: 8 HV_BMS
 SG_ BP08T21 : 0|16@1+ (0.1,0) [0|6553.5] "C"  RPI_LOGGER
 SG_ BP08T22 : 16|16@1+ (0.1,0) [0|6553.5] "C"  RPI_LOGGER
 SG_ BP08T23 : 32|16@1+ (0.1,0) [0|6553.5] "C"  RPI_LOGGER
 SG_ BP08T24 : 48|16@1+ (0.1,0) [0|6553.5] "C"  RPI_LOGGER

BO_ 1936 BP09_T01_04: 8 HV_BMS
 SG_ BP09T01 : 0|16@1+ (0.1,0) [0|6553.5] "C"  RPI_LOGGER
 SG_ BP09T02 : 16|16@1+ (0.1,0) [0|6553.5] "C"  RPI_LOGGER
 SG_ BP09T03 : 32|16@1+ (0.1,0) [0|6553.5] "C"  RPI_LOGGER
 SG_ BP09T04 : 48|16@1+ (0.1,0) [0|6553.5] "C"  RPI_LOGGER

BO_ 1937 BP09_T05_08: 8 HV_BMS
 SG_ BP09T05 : 0|16@1+ (0.1,0) [0|6553.5] "C"  RPI_LOGGER
 SG_ BP09T06 : 16|16@1+ (0.1,0) [0|6553.5] "C"  RPI_LOGGER
 SG_ BP09T07 : 32|16@1+ (0.1,0) [0|6553.5] "C"  RPI_LOGGER
 SG_ BP09T08 : 48|16@1+ (0.1,0) [0|6553.5] "C"  RPI_LOGGER

BO_ 1938 BP09_T09_12: 8 HV_BMS
 SG_ BP09T09 : 0|16@1+ (0.1,0) [0|6553.5] "C"  RPI_LOGGER
 SG_ BP09T10 : 16|16@1+ (0.1,0) [0|6553.5] "C"  RPI_LOGGER
 SG_ BP09T11 : 32|16@1+ (0.1,0) [0|6553.5] "C"  RPI_LOGGER
 SG_ BP09T12 : 48|16@1+ (0.1,0) [0|6553.5] "C"  RPI_LOGGER

BO_ 1939 BP09_T13_16: 8 HV_BMS
 SG_ BP09T13 : 0|16@1+ (0.1,0) [0|6553.5] "C"  RPI_LOGGER
 SG_ BP09T14 : 16|16@1+ (0.1,0) [0|6553.5] "C"  RPI_LOGGER
 SG_ BP09T15 : 32|16@1+ (0.1,0) [0|6553.5] "C"  RPI_LOGGER
 SG_ BP09T16 : 48|16@1+ (0.1,0) [0|6553.5] "C"  RPI_LOGGER

BO_ 1940 BP09_T17_20: 8 HV_BMS
 SG_ BP09T17 : 0|16@1+ (0.1,0) [0|6553.5] "C"  RPI_LOGGER
 SG_ BP09T18 : 16|16@1+ (0.1,0) [0|6553.5] "C"  RPI_LOGGER
 SG_ BP09T19 : 32|16@1+ (0.1,0) [0|6553.5] "C"  RPI_LOGGER
 SG_ BP09T20 : 48|16@1+ (0.1,0) [0|6553.5] "C"  RPI_LOGGER

BO_ 1941 BP09_T21_24: 8 HV_BMS
 SG_ BP09T21 : 0|16@1+ (0.1,0) [0|6553.5] "C"  RPI_LOGGER
 SG_ BP09T22 : 16|16@1+ (0.1,0) [0|6553.5] "C"  RPI_LOGGER
 SG_ BP09T23 : 32|16@1+ (0.1,0) [0|6553.5] "C"  RPI_LOGGER
 SG_ BP09T24 : 48|16@1+ (0.1,0) [0|6553.5] "C"  RPI_LOGGER

BO_ 1942 BP10_T01_04: 8 HV_BMS
 SG_ BP10T01 : 0|16@1+ (0.1,0) [0|6553.5] "C"  RPI_LOGGER
 SG_ BP10T02 : 16|16@1+ (0.1,0) [0|6553.5] "C"  RPI_LOGGER
 SG_ BP10T03 : 32|16@1+ (0.1,0) [0|6553.5] "C"  RPI_LOGGER
 SG_ BP10T04 : 48|16@1+ (0.1,0) [0|6553.5] "C"  RPI_LOGGER

BO_ 1943 BP10_T05_08: 8 HV_BMS
 SG_ BP10T05 : 0|16@1+ (0.1,0) [0|6553.5] "C"  RPI_LOGGER
 SG_ BP10T06 : 16|16@1+ (0.1,0) [0|6553.5] "C"  RPI_LOGGER
 SG_ BP10T07 : 32|16@1+ (0.1,0) [0|6553.5] "C"  RPI_LOGGER
 SG_ BP10T08 : 48|16@1+ (0.1,0) [0|6553.5] "C"  RPI_LOGGER

BO_ 1944 BP10_T09_12: 8 HV_BMS
 SG_ BP10T09 : 0|16@1+ (0.1,0) [0|6553.5] "C"  RPI_LOGGER
 SG_ BP10T10 : 16|16@1+ (0.1,0) [0|6553.5] "C"  RPI_LOGGER
 SG_ BP10T11 : 32|16@1+ (0.1,0) [0|6553.5] "C"  RPI_LOGGER
 SG_ BP10T12 : 48|16@1+ (0.1,0) [0|6553.5] "C"  RPI_LOGGER

BO_ 1945 BP10_T13_16: 8 HV_BMS
 SG_ BP10T13 : 0|16@1+ (0.1,0) [0|6553.5] "C"  RPI_LOGGER
 SG_ BP10T14 : 16|16@1+ (0.1,0) [0|6553.5] "C"  RPI_LOGGER
 SG_ BP10T15 : 32|16@1+ (0.1,0) [0|6553.5] "C"  RPI_LOGGER
 SG_ BP10T16 : 48|16@1+ (0.1,0) [0|6553.5] "C"  RPI_LOGGER

BO_ 1946 BP10_T17_20: 8 HV_BMS
 SG_ BP10T17 : 0|16@1+ (0.1,0) [0|6553.5] "C"  RPI_LOGGER
 SG_ BP10T18 : 16|16@1+ (0.1,0) [0|6553.5] "C"  RPI_LOGGER
 SG_ BP10T19 : 32|16@1+ (0.1,0) [0|6553.5] "C"  RPI_LOGGER
 SG_ BP10T20 : 48|16@1+ (0.1,0) [0|6553.5] "C"  RPI_LOGGER

BO_ 1947 BP10_T21_24: 8 HV_BMS
 SG_ BP10T21 : 0|16@1+ (0.1,0) [0|6553.5] "C"  RPI_LOGGER
 SG_ BP10T22 : 16|16@1+ (0.1,0) [0|6553.5] "C"  RPI_LOGGER
 SG_ BP10T23 : 32|16@1+ (0.1,0) [0|6553.5] "C"  RPI_LOGGER
 SG_ BP10T24 : 48|16@1+ (0.1,0) [0|6553.5] "C"  RPI_LOGGER

BO_ 457 AREO_PRESSURE_sensors13_16: 8 AREO_PRESSURE_SENS
 SG_ AREO_p16 : 55|16@0+ (1,0) [0|65535] ""  RPI_LOGGER
 SG_ AREO_p15 : 39|16@0+ (1,0) [0|65535] ""  RPI_LOGGER
 SG_ AREO_p14 : 23|16@0+ (1,0) [0|65535] ""  RPI_LOGGER
 SG_ AREO_p13 : 7|16@0+ (1,0) [0|65535] ""  RPI_LOGGER

BO_ 456 AREO_PRESSURE_sensors09_12: 8 AREO_PRESSURE_SENS
 SG_ AREO_p9 : 55|16@0+ (1,0) [0|65535] ""  RPI_LOGGER
 SG_ AREO_p12 : 39|16@0+ (1,0) [0|65535] ""  RPI_LOGGER
 SG_ AREO_p11 : 23|16@0+ (1,0) [0|65535] ""  RPI_LOGGER
 SG_ AREO_p10 : 7|16@0+ (1,0) [0|65535] ""  RPI_LOGGER

BO_ 455 AREO_PRESSURE_sensors05_08: 8 AREO_PRESSURE_SENS
 SG_ AREO_p8 : 55|16@0+ (1,0) [0|65535] ""  RPI_LOGGER
 SG_ AREO_p7 : 39|16@0+ (1,0) [0|65535] ""  RPI_LOGGER
 SG_ AREO_p6 : 23|16@0+ (1,0) [0|65535] ""  RPI_LOGGER
 SG_ AREO_p5 : 7|16@0+ (1,0) [0|65535] ""  RPI_LOGGER

BO_ 454 AREO_PRESSURE_sensors01_04: 8 AREO_PRESSURE_SENS
 SG_ AREO_p4 : 55|16@0+ (1,0) [0|65535] ""  RPI_LOGGER
 SG_ AREO_p3 : 39|16@0+ (1,0) [0|65535] ""  RPI_LOGGER
 SG_ AREO_p2 : 23|16@0+ (1,0) [0|65535] ""  RPI_LOGGER
 SG_ AREO_p1 : 7|16@0+ (1,0) [0|65535] ""  RPI_LOGGER

BO_TX_BU_ 1034 : LV_BMS,SW;
BO_TX_BU_ 1039 : MAIN,SW;

BA_DEF_ BO_  "Period" INT 0 10000;
BA_DEF_  "BusType" STRING ;
BA_DEF_DEF_  "Period" 100;
BA_DEF_DEF_  "BusType" "CAN";
BA_ "Period" BO_ 6 10000;
BA_ "Period" BO_ 28 1000;
BA_ "Period" BO_ 1034 10000;
BA_ "Period" BO_ 1328 1000;
BA_ "Period" BO_ 1039 200;
BA_ "Period" BO_ 401 30;
BA_ "Period" BO_ 1327 1000;
BA_ "Period" BO_ 1325 1000;
BA_ "Period" BO_ 1326 1000;
BA_ "Period" BO_ 1324 1000;
BA_ "Period" BO_ 1323 5;
BA_ "Period" BO_ 1322 5;
BA_ "Period" BO_ 1321 5;
BA_ "Period" BO_ 1320 5;
BA_ "Period" BO_ 1319 5;
BA_ "Period" BO_ 1317 200;
BA_ "Period" BO_ 1316 4;
BA_ "Period" BO_ 1315 4;
BA_ "Period" BO_ 1314 4;
BA_ "Period" BO_ 1313 4;
BA_ "Period" BO_ 1036 200;
BA_ "Period" BO_ 1035 200;
BA_ "Period" BO_ 1038 200;
BA_ "Period" BO_ 1407 10000;
BA_ "Period" BO_ 95 4;
BA_ "Period" BO_ 1033 10;
BA_ "Period" BO_ 1032 10;
BA_ "Period" BO_ 99 20;
BA_ "Period" BO_ 1037 200;
VAL_ 1282 Service_brake_state_engaged 3 "Service_brake_state_available" 2 "Service_brake_state_engaged" 1 "Service_brake_state_disengaged" ;
VAL_ 1282 AMI_state 6 "AMI_state_autocross" 5 "AMI_state_inspection" 4 "AMI_state_braketest" 3 "AMI_state_trackdrive" 2 "AMI_state_skidpad" 1 "AMI_state_acceleration" ;
VAL_ 1282 EBS_state 3 "EBS_state_activated" 2 "EBS_state_armed" 1 "EBS_state_unavailable" ;
VAL_ 1282 AS_state 5 "AS_state_finish" 4 "AS_state_emergency_brake" 3 "AS_state_driving " 2 "AS_state_ready" 1 "AS_state_off" ;
